VERSION ""

NS_ :

BS_:

BU_: EHR DMS VIC GWS HASy ADAS MRR_L MRR_M MPC CMRR_RL CMRR_RR CMRR_FL CMRR_FR MRR GW AVAP
VAL_TABLE_ ACC_ICON_LADI 2 "Blinking" 1 "Shown" 0 "Not shown" ;
VAL_TABLE_ ShiftInProgress 1 "shift in progress" 0 "no shift" ;
VAL_TABLE_ ACC_Minimale_Bremsung 1 "Anford_Min_Bremsung_aktiv" 0 "Anford_Min_Bremsung_nicht_aktiv" ;
VAL_TABLE_ ADAS_Lvl_HBA 7 "Reserved" 6 "Reserved" 5 "Reserved" 4 "Reserved" 3 "Level 3" 2 "Level 2" 1 "Level 1" 0 "Level 0" ;
VAL_TABLE_ ADAS_Req_Prefill 1 "Active" 0 "Not Active" ;
VAL_TABLE_ ADAS_Req_AWB 1 "Active" 0 "Not Active" ;
VAL_TABLE_ ADAS_Req_HBA 1 "Active" 0 "Not active" ;
VAL_TABLE_ ADAS_Lvl_AWB 7 "Level 7" 6 "Level 6" 5 "Level 5" 4 "Level 4" 3 "Level 3" 2 "Level 2" 1 "Level 1" 0 "No Request" ;
VAL_TABLE_ ADAS_DecelTyp_AEB 15 "Reserved" 14 "Reserved" 13 "Reserved" 12 "Reserved" 11 "Reserved" 10 "Reserved" 9 "Reserved" 8 "Reserved" 7 "Reserved" 6 "Reserved" 5 "FCTB" 4 "EBA" 3 "AEB~CYCLIST" 2 "AEB~VRU" 1 "AEB" 0 "Default" ;
VAL_TABLE_ ADAS_0x4BA_HMI 15 "off" 14 "reserved" 13 "reserved" 12 "reserved" 11 "reserved" 10 "reserved" 9 "reserved" 8 "blueFlashing" 7 "blueBreathing" 6 "greenFlashing" 5 "greenBreathing" 4 "red/purple" 3 "yellow" 2 "green" 1 "blue" 0 "white" ;

BO_ 3221225472 VECTOR__INDEPENDENT_SIG_MSG: 0 Vector__XXX
 SG_ GRA_ACC_01_CRC : 0|8@1+ (1,0) [0|255] "" Vector__XXX

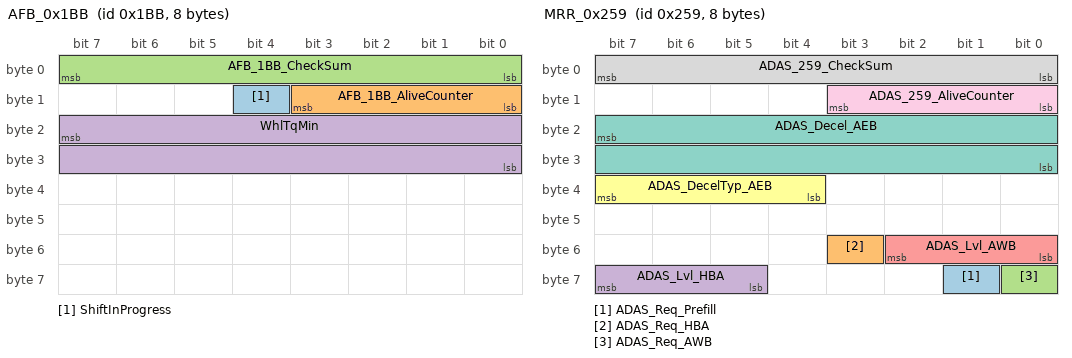
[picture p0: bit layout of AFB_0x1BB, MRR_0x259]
BO_ 443 AFB_0x1BB: 8 HASy
 SG_ ShiftInProgress : 12|1@0+ (1,0) [0|1] ""  ADAS
 SG_ AFB_1BB_AliveCounter : 11|4@0+ (1,0) [0|15] ""  ADAS
 SG_ AFB_1BB_CheckSum : 7|8@0+ (1,0) [0|255] ""  ADAS
 SG_ WhlTqMin : 23|16@0+ (1,-32768) [-32768|32767] "Nm"  ADAS

BO_ 601 MRR_0x259: 8 MRR
 SG_ ADAS_Req_Prefill : 57|1@0+ (1,0) [0|1] ""  GW
 SG_ ADAS_Req_HBA : 51|1@0+ (1,0) [0|1] ""  GW
 SG_ ADAS_Req_AWB : 56|1@0+ (1,0) [0|1] ""  GW
 SG_ ADAS_Lvl_HBA : 63|3@0+ (1,0) [0|7] ""  GW
 SG_ ADAS_Lvl_AWB : 50|3@0+ (1,0) [0|7] ""  GW
 SG_ ADAS_DecelTyp_AEB : 39|4@0+ (1,0) [0|15] ""  GW
 SG_ ADAS_Decel_AEB : 23|16@0+ (0.0004882,-16) [-16|15.994187] "m/s²"  GW
 SG_ ADAS_259_CheckSum : 7|8@0+ (1,0) [0|255] ""  GW
 SG_ ADAS_259_AliveCounter : 11|4@0+ (1,0) [0|15] ""  GW

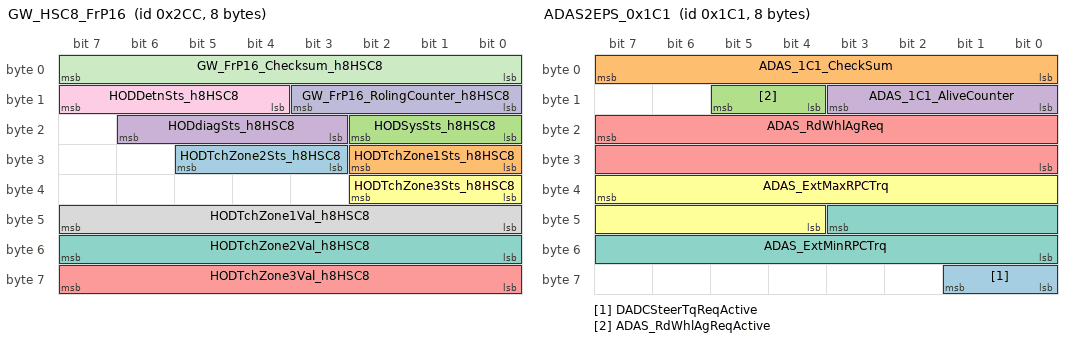
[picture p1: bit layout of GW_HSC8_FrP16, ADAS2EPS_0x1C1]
BO_ 716 GW_HSC8_FrP16: 8 GW
 SG_ HODTchZone2Sts_h8HSC8 : 27|3@1+ (1,0) [0|7] ""  ADAS
 SG_ HODTchZone1Sts_h8HSC8 : 24|3@1+ (1,0) [0|7] ""  ADAS
 SG_ HODSysSts_h8HSC8 : 16|3@1+ (1,0) [0|7] ""  ADAS
 SG_ HODdiagSts_h8HSC8 : 19|4@1+ (1,0) [0|15] ""  ADAS
 SG_ HODTchZone3Val_h8HSC8 : 56|8@1+ (1,0) [0|255] ""  ADAS
 SG_ HODTchZone3Sts_h8HSC8 : 32|3@1+ (1,0) [0|7] ""  ADAS
 SG_ HODTchZone2Val_h8HSC8 : 48|8@1+ (1,0) [0|255] ""  ADAS
 SG_ HODTchZone1Val_h8HSC8 : 40|8@1+ (1,0) [0|255] ""  ADAS
 SG_ HODDetnSts_h8HSC8 : 12|4@1+ (1,0) [0|15] ""  ADAS
 SG_ GW_FrP16_RolingCounter_h8HSC8 : 8|4@1+ (1,0) [0|15] ""  ADAS
 SG_ GW_FrP16_Checksum_h8HSC8 : 0|8@1+ (1,0) [0|255] ""  ADAS

BO_ 449 ADAS2EPS_0x1C1: 8 ADAS
 SG_ DADCSteerTqReqActive : 57|2@0+ (1,0) [0|3] ""  HASy
 SG_ ADAS_1C1_CheckSum : 7|8@0+ (1,0) [0|255] ""  HASy
 SG_ ADAS_RdWhlAgReqActive : 13|2@0+ (1,0) [0|3] ""  HASy
 SG_ ADAS_1C1_AliveCounter : 11|4@0+ (1,0) [0|15] ""  HASy
 SG_ ADAS_RdWhlAgReq : 23|16@0+ (0.005,-45) [-45|45] "degree"  HASy
 SG_ ADAS_ExtMaxRPCTrq : 39|12@0+ (0.02,-20.48) [-20.48|20.46] "Nm"  HASy
 SG_ ADAS_ExtMinRPCTrq : 43|12@0+ (0.02,-20.48) [-20.48|20.46] "Nm"  HASy

BO_ 1216 HDM_GF: 32 EHR
 SG_ GF_map_position_accuracy : 200|12@1+ (1,0) [0|4095] "cm"  ADAS
 SG_ GF_map_position_deviation : 188|12@1+ (1,0) [0|4095] "cm"  ADAS
 SG_ GF_CRC : 0|16@1+ (1,0) [0|65535] ""  ADAS
 SG_ GF_AliveCtr : 16|8@1+ (1,0) [0|255] ""  ADAS
 SG_ GF_Currentlane_Index : 176|8@1+ (1,0) [0|255] ""  ADAS
 SG_ GF_NumberOfLanes : 184|4@1+ (1,0) [0|15] ""  ADAS
 SG_ GF_Region_outOfODD_offset : 24|10@1+ (1,0) [0|1023] "m"  ADAS
 SG_ GF_Country_outOfODD_offset : 34|10@1+ (1,0) [0|1023] "m"  ADAS
 SG_ GF_LaneTrans_outOfODD_offset : 44|10@1+ (1,0) [0|1023] "m"  ADAS
 SG_ GF_Curvature_outOfODD_offset : 54|10@1+ (1,0) [0|1023] "m"  ADAS
 SG_ GF_LaneType_outOfODD_offset : 64|10@1+ (1,0) [0|1023] "m"  ADAS
 SG_ GF_RoadSlope_outOfODD_offset : 74|10@1+ (1,0) [0|1023] "m"  ADAS
 SG_ GF_LaneWidth_outOfODD_offset : 84|10@1+ (1,0) [0|1023] "m"  ADAS
 SG_ GF_FormOfWay_outOfODD_offset : 94|10@1+ (1,0) [0|1023] "m"  ADAS
 SG_ GF_MapExpired : 224|1@1+ (1,0) [0|1] "boolean"  ADAS
 SG_ GF_BlackListedSegment_offset : 114|10@1+ (1,0) [0|1023] "m"  ADAS
 SG_ GF_Intersection_offset : 104|10@1+ (1,0) [0|1023] "m"  ADAS
 SG_ GF_SideWind_offset : 124|10@1+ (1,0) [0|1023] "m"  ADAS
 SG_ GF_ActiveSpeedLimit : 168|8@1+ (1,0) [0|255] "km/h"  ADAS
 SG_ GF_TollGate_offset : 134|10@1+ (1,0) [0|1023] "m"  ADAS
 SG_ GF_TrafficLight_offset : 144|10@1+ (1,0) [0|1023] "m"  ADAS
 SG_ GF_Tunnel_Offset : 154|10@1+ (1,0) [0|1023] "m"  ADAS
 SG_ GF_MapStatus : 212|10@1+ (1,0) [0|1023] ""  ADAS

BO_ 1217 HDM_Curv: 64 EHR
 SG_ Cv_CRC : 0|16@1+ (1,0) [0|65535] ""  ADAS
 SG_ Cv_AliveCtr : 16|8@1+ (1,0) [0|255] ""  ADAS
 SG_ Cv_Value_Seg00 : 32|10@1+ (0.0001,0) [0|0.1] "1/m"  ADAS
 SG_ Cv_Value_Seg01 : 42|10@1+ (0.0001,0) [0|0.1] "1/m"  ADAS
 SG_ Cv_Value_Seg02 : 52|10@1+ (0.0001,0) [0|0.1] "1/m"  ADAS
 SG_ Cv_Value_Seg03 : 62|10@1+ (0.0001,0) [0|0.1] "1/m"  ADAS
 SG_ Cv_Value_Seg04 : 72|10@1+ (0.0001,0) [0|0.1] "1/m"  ADAS
 SG_ Cv_Value_Seg05 : 82|10@1+ (0.0001,0) [0|0.1] "1/m"  ADAS
 SG_ Cv_Value_Seg06 : 92|10@1+ (0.0001,0) [0|0.1] "1/m"  ADAS
 SG_ Cv_Value_Seg07 : 102|10@1+ (0.0001,0) [0|0.1] "1/m"  ADAS
 SG_ Cv_Value_Seg08 : 112|10@1+ (0.0001,0) [0|0.1] "1/m"  ADAS
 SG_ Cv_Value_Seg09 : 122|10@1+ (0.0001,0) [0|0.1] "1/m"  ADAS
 SG_ Cv_Value_Seg10 : 132|10@1+ (0.0001,0) [0|0.1] "1/m"  ADAS
 SG_ Cv_Value_Seg11 : 142|10@1+ (0.0001,0) [0|0.1] "1/m"  ADAS
 SG_ Cv_Value_Seg12 : 152|10@1+ (0.0001,0) [0|0.1] "1/m"  ADAS
 SG_ Cv_Value_Seg13 : 162|10@1+ (0.0001,0) [0|0.1] "1/m"  ADAS
 SG_ Cv_Value_Seg14 : 172|10@1+ (0.0001,0) [0|0.1] "1/m"  ADAS
 SG_ Cv_Value_Seg15 : 182|10@1+ (0.0001,0) [0|0.1] "1/m"  ADAS
 SG_ Cv_Value_Seg16 : 192|10@1+ (0.0001,0) [0|0.1] "1/m"  ADAS
 SG_ Cv_Value_Seg17 : 202|10@1+ (0.0001,0) [0|0.1] "1/m"  ADAS
 SG_ Cv_Value_Seg18 : 212|10@1+ (0.0001,0) [0|0.1] "1/m"  ADAS
 SG_ Cv_Value_Seg19 : 222|10@1+ (0.0001,0) [0|0.1] "1/m"  ADAS
 SG_ Cv_Offset_Seg00 : 232|10@1+ (1,0) [0|1023] "m"  ADAS
 SG_ Cv_Offset_Seg01 : 242|10@1+ (1,0) [0|1023] "m"  ADAS
 SG_ Cv_Offset_Seg02 : 252|10@1+ (1,0) [0|1023] "m"  ADAS
 SG_ Cv_Offset_Seg03 : 262|10@1+ (1,0) [0|1023] "m"  ADAS
 SG_ Cv_Offset_Seg04 : 272|10@1+ (1,0) [0|1023] "m"  ADAS
 SG_ Cv_Offset_Seg05 : 282|10@1+ (1,0) [0|1023] "m"  ADAS
 SG_ Cv_Offset_Seg06 : 292|10@1+ (1,0) [0|1023] "m"  ADAS
 SG_ Cv_Offset_Seg07 : 302|10@1+ (1,0) [0|1023] "m"  ADAS
 SG_ Cv_Offset_Seg08 : 312|10@1+ (1,0) [0|1023] "m"  ADAS
 SG_ Cv_Offset_Seg09 : 322|10@1+ (1,0) [0|1023] "m"  ADAS
 SG_ Cv_Offset_Seg10 : 332|10@1+ (1,0) [0|1023] "m"  ADAS
 SG_ Cv_Offset_Seg11 : 342|10@1+ (1,0) [0|1023] "m"  ADAS
 SG_ Cv_Offset_Seg12 : 352|10@1+ (1,0) [0|1023] "m"  ADAS
 SG_ Cv_Offset_Seg13 : 362|10@1+ (1,0) [0|1023] "m"  ADAS
 SG_ Cv_Offset_Seg14 : 372|10@1+ (1,0) [0|1023] "m"  ADAS
 SG_ Cv_Offset_Seg15 : 382|10@1+ (1,0) [0|1023] "m"  ADAS
 SG_ Cv_Offset_Seg16 : 392|10@1+ (1,0) [0|1023] "m"  ADAS
 SG_ Cv_Offset_Seg17 : 402|10@1+ (1,0) [0|1023] "m"  ADAS
 SG_ Cv_Offset_Seg18 : 412|10@1+ (1,0) [0|1023] "m"  ADAS
 SG_ Cv_Offset_Seg19 : 422|10@1+ (1,0) [0|1023] "m"  ADAS

BO_ 1220 HDM_Central_Line_M: 24 EHR
 SG_ centerline_m_CRC : 0|16@1+ (1,0) [0|65535] ""  ADAS
 SG_ centerline_m_AliveCtr : 16|8@1+ (1,0) [0|255] ""  ADAS
 SG_ centerline_m_BlockCtr : 24|4@1+ (1,0) [0|15] ""  ADAS
 SG_ CenterPoint_dx_m01 : 28|10@1+ (0.05,-50) [-50|0] "m"  ADAS
 SG_ CenterPoint_dy_m01 : 38|12@1+ (0.05,-102.4) [-102.4|102.35] "m"  ADAS
 SG_ CenterPoint_dx_m02 : 50|10@1+ (0.05,-50) [-50|0] "m"  ADAS
 SG_ CenterPoint_dy_m02 : 60|12@1+ (0.05,-102.4) [-102.4|102.35] "m"  ADAS
 SG_ CenterPoint_dx_m03 : 72|10@1+ (0.05,-50) [-50|0] "m"  ADAS
 SG_ CenterPoint_dy_m03 : 82|12@1+ (0.05,-102.4) [-102.4|102.35] "m"  ADAS
 SG_ CenterPoint_dx_m04 : 94|10@1+ (0.05,-50) [-50|0] "m"  ADAS
 SG_ CenterPoint_dy_m04 : 104|12@1+ (0.05,-102.4) [-102.4|102.35] "m"  ADAS
 SG_ MAP_TimeSync : 116|48@1+ (1,0) [0|39636172800000] "ms"  ADAS

BO_ 1218 HDM_Centerline_1: 64 EHR
 SG_ centerline_1_CRC : 0|16@1+ (1,0) [0|65535] ""  ADAS
 SG_ centerline_1_AliveCtr : 16|8@1+ (1,0) [0|255] ""  ADAS
 SG_ CenterPoint_dx_00 : 24|12@1+ (0.05,0) [0|204.75] "m"  ADAS
 SG_ CenterPoint_dy_00 : 36|12@1+ (0.05,-102.4) [-102.4|102.35] "m"  ADAS
 SG_ CenterPoint_dx_01 : 48|12@1+ (0.05,0) [0|204.75] "m"  ADAS
 SG_ CenterPoint_dy_01 : 60|12@1+ (0.05,-102.4) [-102.4|102.35] "m"  ADAS
 SG_ CenterPoint_dx_02 : 72|12@1+ (0.05,0) [0|204.75] "m"  ADAS
 SG_ CenterPoint_dy_02 : 84|12@1+ (0.05,-102.4) [-102.4|102.35] "m"  ADAS
 SG_ CenterPoint_dx_03 : 96|12@1+ (0.05,0) [0|204.75] "m"  ADAS
 SG_ CenterPoint_dy_03 : 108|12@1+ (0.05,-102.4) [-102.4|102.35] "m"  ADAS
 SG_ CenterPoint_dx_04 : 120|12@1+ (0.05,0) [0|204.75] "m"  ADAS
 SG_ CenterPoint_dy_04 : 132|12@1+ (0.05,-102.4) [-102.4|102.35] "m"  ADAS
 SG_ CenterPoint_dx_05 : 144|12@1+ (0.05,0) [0|204.75] "m"  ADAS
 SG_ CenterPoint_dy_05 : 156|12@1+ (0.05,-102.4) [-102.4|102.35] "m"  ADAS
 SG_ CenterPoint_dx_06 : 168|12@1+ (0.05,0) [0|204.75] "m"  ADAS
 SG_ CenterPoint_dy_06 : 180|12@1+ (0.05,-102.4) [-102.4|102.35] "m"  ADAS
 SG_ CenterPoint_dx_07 : 192|12@1+ (0.05,0) [0|204.75] "m"  ADAS
 SG_ CenterPoint_dy_07 : 204|12@1+ (0.05,-102.4) [-102.4|102.35] "m"  ADAS
 SG_ CenterPoint_dx_08 : 216|12@1+ (0.05,0) [0|204.75] "m"  ADAS
 SG_ CenterPoint_dy_08 : 228|12@1+ (0.05,-102.4) [-102.4|102.35] "m"  ADAS
 SG_ CenterPoint_dx_09 : 240|12@1+ (0.05,0) [0|204.75] "m"  ADAS
 SG_ CenterPoint_dy_09 : 252|12@1+ (0.05,-102.4) [-102.4|102.35] "m"  ADAS
 SG_ CenterPoint_dx_10 : 264|12@1+ (0.05,0) [0|204.75] "m"  ADAS
 SG_ CenterPoint_dy_10 : 276|12@1+ (0.05,-102.4) [-102.4|102.35] "m"  ADAS
 SG_ CenterPoint_dx_11 : 288|12@1+ (0.05,0) [0|204.75] "m"  ADAS
 SG_ CenterPoint_dy_11 : 300|12@1+ (0.05,-102.4) [-102.4|102.35] "m"  ADAS
 SG_ CenterPoint_dx_12 : 312|12@1+ (0.05,0) [0|204.75] "m"  ADAS
 SG_ CenterPoint_dy_12 : 324|12@1+ (0.05,-102.4) [-102.4|102.35] "m"  ADAS
 SG_ CenterPoint_dx_13 : 336|12@1+ (0.05,0) [0|204.75] "m"  ADAS
 SG_ CenterPoint_dy_13 : 348|12@1+ (0.05,-102.4) [-102.4|102.35] "m"  ADAS
 SG_ CenterPoint_dx_14 : 360|12@1+ (0.05,0) [0|204.75] "m"  ADAS
 SG_ CenterPoint_dy_14 : 372|12@1+ (0.05,-102.4) [-102.4|102.35] "m"  ADAS
 SG_ CenterPoint_dx_15 : 384|12@1+ (0.05,0) [0|204.75] "m"  ADAS
 SG_ CenterPoint_dy_15 : 396|12@1+ (0.05,-102.4) [-102.4|102.35] "m"  ADAS
 SG_ CenterPoint_dx_16 : 408|12@1+ (0.05,0) [0|204.75] "m"  ADAS
 SG_ CenterPoint_dy_16 : 420|12@1+ (0.05,-102.4) [-102.4|102.35] "m"  ADAS
 SG_ CenterPoint_dx_17 : 432|12@1+ (0.05,0) [0|204.75] "m"  ADAS
 SG_ CenterPoint_dy_17 : 444|12@1+ (0.05,-102.4) [-102.4|102.35] "m"  ADAS
 SG_ CenterPoint_dx_18 : 456|12@1+ (0.05,0) [0|204.75] "m"  ADAS
 SG_ CenterPoint_dy_18 : 468|12@1+ (0.05,-102.4) [-102.4|102.35] "m"  ADAS
 SG_ CenterPoint_dx_19 : 480|12@1+ (0.05,0) [0|204.75] "m"  ADAS
 SG_ CenterPoint_dy_19 : 492|12@1+ (0.05,-102.4) [-102.4|102.35] "m"  ADAS
 SG_ centerline_1_BlockCtr : 504|4@1+ (1,0) [0|15] ""  ADAS

BO_ 1219 HDM_Centerline_2: 64 EHR
 SG_ centerline_2_CRC : 0|16@1+ (1,0) [0|65535] ""  ADAS
 SG_ centerline_2_AliveCtr : 16|8@1+ (1,0) [0|255] ""  ADAS
 SG_ CenterPoint_dx_20 : 24|12@1+ (0.05,0) [0|204.75] "m"  ADAS
 SG_ CenterPoint_dy_20 : 36|12@1+ (0.05,-102.4) [-102.4|102.35] "m"  ADAS
 SG_ CenterPoint_dx_21 : 48|12@1+ (0.05,0) [0|204.75] "m"  ADAS
 SG_ CenterPoint_dy_21 : 60|12@1+ (0.05,-102.4) [-102.4|102.35] "m"  ADAS
 SG_ CenterPoint_dx_22 : 72|12@1+ (0.05,0) [0|204.75] "m"  ADAS
 SG_ CenterPoint_dy_22 : 84|12@1+ (0.05,-102.4) [-102.4|102.35] "m"  ADAS
 SG_ CenterPoint_dx_23 : 96|12@1+ (0.05,0) [0|204.75] "m"  ADAS
 SG_ CenterPoint_dy_23 : 108|12@1+ (0.05,-102.4) [-102.4|102.35] "m"  ADAS
 SG_ CenterPoint_dx_24 : 120|12@1+ (0.05,0) [0|204.75] "m"  ADAS
 SG_ CenterPoint_dy_24 : 132|12@1+ (0.05,-102.4) [-102.4|102.35] "m"  ADAS
 SG_ CenterPoint_dx_25 : 144|12@1+ (0.05,0) [0|204.75] "m"  ADAS
 SG_ CenterPoint_dy_25 : 156|12@1+ (0.05,-102.4) [-102.4|102.35] "m"  ADAS
 SG_ CenterPoint_dx_26 : 168|12@1+ (0.05,0) [0|204.75] "m"  ADAS
 SG_ CenterPoint_dy_26 : 180|12@1+ (0.05,-102.4) [-102.4|102.35] "m"  ADAS
 SG_ CenterPoint_dx_27 : 192|12@1+ (0.05,0) [0|204.75] "m"  ADAS
 SG_ CenterPoint_dy_27 : 204|12@1+ (0.05,-102.4) [-102.4|102.35] "m"  ADAS
 SG_ CenterPoint_dx_28 : 216|12@1+ (0.05,0) [0|204.75] "m"  ADAS
 SG_ CenterPoint_dy_28 : 228|12@1+ (0.05,-102.4) [-102.4|102.35] "m"  ADAS
 SG_ CenterPoint_dx_29 : 240|12@1+ (0.05,0) [0|204.75] "m"  ADAS
 SG_ CenterPoint_dy_29 : 252|12@1+ (0.05,-102.4) [-102.4|102.35] "m"  ADAS
 SG_ CenterPoint_dx_30 : 264|12@1+ (0.05,0) [0|204.75] "m"  ADAS
 SG_ CenterPoint_dy_30 : 276|12@1+ (0.05,-102.4) [-102.4|102.35] "m"  ADAS
 SG_ CenterPoint_dx_31 : 288|12@1+ (0.05,0) [0|204.75] "m"  ADAS
 SG_ CenterPoint_dy_31 : 300|12@1+ (0.05,-102.4) [-102.4|102.35] "m"  ADAS
 SG_ CenterPoint_dx_32 : 312|12@1+ (0.05,0) [0|204.75] "m"  ADAS
 SG_ CenterPoint_dy_32 : 324|12@1+ (0.05,-102.4) [-102.4|102.35] "m"  ADAS
 SG_ CenterPoint_dx_33 : 336|12@1+ (0.05,0) [0|204.75] "m"  ADAS
 SG_ CenterPoint_dy_33 : 348|12@1+ (0.05,-102.4) [-102.4|102.35] "m"  ADAS
 SG_ CenterPoint_dx_34 : 360|12@1+ (0.05,0) [0|204.75] "m"  ADAS
 SG_ CenterPoint_dy_34 : 372|12@1+ (0.05,-102.4) [-102.4|102.35] "m"  ADAS
 SG_ centerline_LaneWidth : 384|9@1+ (1,0) [0|511] "cm"  ADAS
 SG_ localization_lat_StdDev : 393|12@1+ (0.01,0) [0|40.95] "m"  ADAS
 SG_ localization_long_StdDev : 405|12@1+ (0.01,0) [0|40.95] "m"  ADAS
 SG_ localization_heading_StdDev : 417|11@1+ (0.1,0) [0|204.7] "degree"  ADAS
 SG_ map_position_deviation : 428|12@1+ (1,0) [0|4095] "cm"  ADAS
 SG_ map_position_accuracy : 440|12@1+ (1,0) [0|4095] "cm"  ADAS
 SG_ Timestamp : 452|20@1+ (0.00065536,0) [0|687.194112] "s"  ADAS
 SG_ centerline_2_BlockCtr : 472|4@1+ (1,0) [0|15] ""  ADAS

BO_ 1221 HDM_Central_Line_HighR: 64 EHR
 SG_ centerline_HR_CRC : 0|16@1+ (1,0) [0|65535] ""  ADAS
 SG_ centerline_HR_AliveCtr : 16|8@1+ (1,0) [0|255] ""  ADAS
 SG_ centerline_HR_BlockCtr : 24|4@1+ (1,0) [0|15] ""  ADAS
 SG_ CenterPoint_dx_m01_HighR : 28|6@1+ (0.001,0) [0|0.049] "m"  ADAS
 SG_ CenterPoint_dy_m01_HighR : 34|6@1+ (0.001,0) [0|0.049] "m"  ADAS
 SG_ CenterPoint_dy_m02_HighR : 40|6@1+ (0.001,0) [0|0.049] "m"  ADAS
 SG_ CenterPoint_dx_m02_HighR : 46|6@1+ (0.001,0) [0|0.049] "m"  ADAS
 SG_ CenterPoint_dy_m03_HighR : 52|6@1+ (0.001,0) [0|0.049] "m"  ADAS
 SG_ CenterPoint_dx_m03_HighR : 58|6@1+ (0.001,0) [0|0.049] "m"  ADAS
 SG_ CenterPoint_dy_m04_HighR : 64|6@1+ (0.001,0) [0|0.049] "m"  ADAS
 SG_ CenterPoint_dx_m04_HighR : 70|6@1+ (0.001,0) [0|0.049] "m"  ADAS
 SG_ CenterPoint_dy_00_HighR : 76|6@1+ (0.001,0) [0|0.049] "m"  ADAS
 SG_ CenterPoint_dx_00_HighR : 82|6@1+ (0.001,0) [0|0.049] "m"  ADAS
 SG_ CenterPoint_dy_01_HighR : 88|6@1+ (0.001,0) [0|0.049] "m"  ADAS
 SG_ CenterPoint_dx_01_HighR : 94|6@1+ (0.001,0) [0|0.049] "m"  ADAS
 SG_ CenterPoint_dy_02_HighR : 100|6@1+ (0.001,0) [0|0.049] "m"  ADAS
 SG_ CenterPoint_dx_02_HighR : 106|6@1+ (0.001,0) [0|0.049] "m"  ADAS
 SG_ CenterPoint_dy_03_HighR : 112|6@1+ (0.001,0) [0|0.049] "m"  ADAS
 SG_ CenterPoint_dx_03_HighR : 118|6@1+ (0.001,0) [0|0.049] "m"  ADAS
 SG_ CenterPoint_dy_04_HighR : 124|6@1+ (0.001,0) [0|0.049] "m"  ADAS
 SG_ CenterPoint_dx_04_HighR : 130|6@1+ (0.001,0) [0|0.049] "m"  ADAS
 SG_ CenterPoint_dy_05_HighR : 136|6@1+ (0.001,0) [0|0.049] "m"  ADAS
 SG_ CenterPoint_dx_05_HighR : 142|6@1+ (0.001,0) [0|0.049] "m"  ADAS
 SG_ CenterPoint_dy_06_HighR : 148|6@1+ (0.001,0) [0|0.049] "m"  ADAS
 SG_ CenterPoint_dx_06_HighR : 154|6@1+ (0.001,0) [0|0.049] "m"  ADAS
 SG_ CenterPoint_dy_07_HighR : 160|6@1+ (0.001,0) [0|0.049] "m"  ADAS
 SG_ CenterPoint_dx_07_HighR : 166|6@1+ (0.001,0) [0|0.049] "m"  ADAS
 SG_ CenterPoint_dy_08_HighR : 172|6@1+ (0.001,0) [0|0.049] "m"  ADAS
 SG_ CenterPoint_dx_08_HighR : 178|6@1+ (0.001,0) [0|0.049] "m"  ADAS
 SG_ CenterPoint_dy_09_HighR : 184|6@1+ (0.001,0) [0|0.049] "m"  ADAS
 SG_ CenterPoint_dx_09_HighR : 190|6@1+ (0.001,0) [0|0.049] "m"  ADAS
 SG_ CenterPoint_dy_10_HighR : 196|6@1+ (0.001,0) [0|0.049] "m"  ADAS
 SG_ CenterPoint_dx_10_HighR : 202|6@1+ (0.001,0) [0|0.049] "m"  ADAS
 SG_ CenterPoint_dy_11_HighR : 208|6@1+ (0.001,0) [0|0.049] "m"  ADAS
 SG_ CenterPoint_dx_11_HighR : 214|6@1+ (0.001,0) [0|0.049] "m"  ADAS
 SG_ CenterPoint_dy_12_HighR : 220|6@1+ (0.001,0) [0|0.049] "m"  ADAS
 SG_ CenterPoint_dx_12_HighR : 226|6@1+ (0.001,0) [0|0.049] "m"  ADAS
 SG_ CenterPoint_dy_13_HighR : 232|6@1+ (0.001,0) [0|0.049] "m"  ADAS
 SG_ CenterPoint_dx_13_HighR : 238|6@1+ (0.001,0) [0|0.049] "m"  ADAS
 SG_ CenterPoint_dy_14_HighR : 244|6@1+ (0.001,0) [0|0.049] "m"  ADAS
 SG_ CenterPoint_dx_14_HighR : 250|6@1+ (0.001,0) [0|0.049] "m"  ADAS
 SG_ CenterPoint_dy_15_HighR : 256|6@1+ (0.001,0) [0|0.049] "m"  ADAS
 SG_ CenterPoint_dx_15_HighR : 262|6@1+ (0.001,0) [0|0.049] "m"  ADAS
 SG_ CenterPoint_dy_16_HighR : 268|6@1+ (0.001,0) [0|0.049] "m"  ADAS
 SG_ CenterPoint_dx_16_HighR : 274|6@1+ (0.001,0) [0|0.049] "m"  ADAS
 SG_ CenterPoint_dy_17_HighR : 280|6@1+ (0.001,0) [0|0.049] "m"  ADAS
 SG_ CenterPoint_dx_17_HighR : 286|6@1+ (0.001,0) [0|0.049] "m"  ADAS
 SG_ CenterPoint_dy_18_HighR : 292|6@1+ (0.001,0) [0|0.049] "m"  ADAS
 SG_ CenterPoint_dx_18_HighR : 298|6@1+ (0.001,0) [0|0.049] "m"  ADAS
 SG_ CenterPoint_dy_19_HighR : 304|6@1+ (0.001,0) [0|0.049] "m"  ADAS
 SG_ CenterPoint_dx_19_HighR : 310|6@1+ (0.001,0) [0|0.049] "m"  ADAS
 SG_ CenterPoint_dy_20_HighR : 316|6@1+ (0.001,0) [0|0.049] "m"  ADAS
 SG_ CenterPoint_dx_20_HighR : 322|6@1+ (0.001,0) [0|0.049] "m"  ADAS
 SG_ CenterPoint_dy_21_HighR : 328|6@1+ (0.001,0) [0|0.049] "m"  ADAS
 SG_ CenterPoint_dx_21_HighR : 334|6@1+ (0.001,0) [0|0.049] "m"  ADAS
 SG_ CenterPoint_dy_22_HighR : 340|6@1+ (0.001,0) [0|0.049] "m"  ADAS
 SG_ CenterPoint_dx_22_HighR : 346|6@1+ (0.001,0) [0|0.049] "m"  ADAS
 SG_ CenterPoint_dy_23_HighR : 352|6@1+ (0.001,0) [0|0.049] "m"  ADAS
 SG_ CenterPoint_dx_23_HighR : 358|6@1+ (0.001,0) [0|0.049] "m"  ADAS
 SG_ CenterPoint_dy_24_HighR : 364|6@1+ (0.001,0) [0|0.049] "m"  ADAS
 SG_ CenterPoint_dx_24_HighR : 370|6@1+ (0.001,0) [0|0.049] "m"  ADAS
 SG_ CenterPoint_dy_25_HighR : 376|6@1+ (0.001,0) [0|0.049] "m"  ADAS
 SG_ CenterPoint_dx_25_HighR : 382|6@1+ (0.001,0) [0|0.049] "m"  ADAS
 SG_ CenterPoint_dy_26_HighR : 388|6@1+ (0.001,0) [0|0.049] "m"  ADAS
 SG_ CenterPoint_dx_26_HighR : 394|6@1+ (0.001,0) [0|0.049] "m"  ADAS
 SG_ CenterPoint_dy_27_HighR : 400|6@1+ (0.001,0) [0|0.049] "m"  ADAS
 SG_ CenterPoint_dx_27_HighR : 406|6@1+ (0.001,0) [0|0.049] "m"  ADAS
 SG_ CenterPoint_dy_28_HighR : 412|6@1+ (0.001,0) [0|0.049] "m"  ADAS
 SG_ CenterPoint_dx_28_HighR : 418|6@1+ (0.001,0) [0|0.049] "m"  ADAS
 SG_ CenterPoint_dy_29_HighR : 424|6@1+ (0.001,0) [0|0.049] "m"  ADAS
 SG_ CenterPoint_dx_29_HighR : 430|6@1+ (0.001,0) [0|0.049] "m"  ADAS
 SG_ CenterPoint_dy_30_HighR : 436|6@1+ (0.001,0) [0|0.049] "m"  ADAS
 SG_ CenterPoint_dx_30_HighR : 442|6@1+ (0.001,0) [0|0.049] "m"  ADAS
 SG_ CenterPoint_dy_31_HighR : 448|6@1+ (0.001,0) [0|0.049] "m"  ADAS
 SG_ CenterPoint_dx_31_HighR : 454|6@1+ (0.001,0) [0|0.049] "m"  ADAS
 SG_ CenterPoint_dy_32_HighR : 460|6@1+ (0.001,0) [0|0.049] "m"  ADAS
 SG_ CenterPoint_dx_32_HighR : 466|6@1+ (0.001,0) [0|0.049] "m"  ADAS
 SG_ CenterPoint_dy_33_HighR : 472|6@1+ (0.001,0) [0|0.049] "m"  ADAS
 SG_ CenterPoint_dx_33_HighR : 478|6@1+ (0.001,0) [0|0.049] "m"  ADAS
 SG_ CenterPoint_dy_34_HighR : 484|6@1+ (0.001,0) [0|0.049] "m"  ADAS
 SG_ CenterPoint_dx_34_HighR : 490|6@1+ (0.001,0) [0|0.049] "m"  ADAS

BO_ 1226 EHR_ReferenceLine1_0x4CA: 64 EHR
 SG_ ReferenceLine1_CRC : 0|16@1+ (1,0) [0|65535] ""  ADAS
 SG_ ReferenceLine1_AliveCtr : 16|8@1+ (1,0) [0|255] ""  ADAS
 SG_ ReferenceLine1_TimeStamp : 24|20@1+ (0.00065536,0) [0|687.194] "s"  ADAS
 SG_ ReferenceLine_point_N : 44|6@1+ (1,0) [0|63] ""  ADAS
 SG_ ReferenceLine_dx_00 : 50|12@1+ (0.05,0) [0|204.75] "m"  ADAS
 SG_ ReferenceLine_dy_00 : 62|12@1+ (0.05,-102.4) [-102.4|102.35] "m"  ADAS
 SG_ ReferenceLine_dx_01 : 74|12@1+ (0.05,0) [0|204.75] "m"  ADAS
 SG_ ReferenceLine_dy_01 : 86|12@1+ (0.05,-102.4) [-102.4|102.35] "m"  ADAS
 SG_ ReferenceLine_dx_02 : 98|12@1+ (0.05,0) [0|204.75] "m"  ADAS
 SG_ ReferenceLine_dy_02 : 110|12@1+ (0.05,-102.4) [-102.4|102.35] "m"  ADAS
 SG_ ReferenceLine_dx_03 : 122|12@1+ (0.05,0) [0|204.75] "m"  ADAS
 SG_ ReferenceLine_dy_03 : 134|12@1+ (0.05,-102.4) [-102.4|102.35] "m"  ADAS
 SG_ ReferenceLine_dx_04 : 146|12@1+ (0.05,0) [0|204.75] "m"  ADAS
 SG_ ReferenceLine_dy_04 : 158|12@1+ (0.05,-102.4) [-102.4|102.35] "m"  ADAS
 SG_ ReferenceLine_dx_05 : 170|12@1+ (0.05,0) [0|204.75] "m"  ADAS
 SG_ ReferenceLine_dy_05 : 182|12@1+ (0.05,-102.4) [-102.4|102.35] "m"  ADAS
 SG_ ReferenceLine_dx_06 : 194|12@1+ (0.05,0) [0|204.75] "m"  ADAS
 SG_ ReferenceLine_dy_06 : 206|12@1+ (0.05,-102.4) [-102.4|102.35] "m"  ADAS
 SG_ ReferenceLine_dx_07 : 218|12@1+ (0.05,0) [0|204.75] "m"  ADAS
 SG_ ReferenceLine_dy_07 : 230|12@1+ (0.05,-102.4) [-102.4|102.35] "m"  ADAS
 SG_ ReferenceLine_dx_08 : 242|12@1+ (0.05,0) [0|204.75] "m"  ADAS
 SG_ ReferenceLine_dy_08 : 254|12@1+ (0.05,-102.4) [-102.4|102.35] "m"  ADAS
 SG_ ReferenceLine_dx_09 : 266|12@1+ (0.05,0) [0|204.75] "m"  ADAS
 SG_ ReferenceLine_dy_09 : 278|12@1+ (0.05,-102.4) [-102.4|102.35] "m"  ADAS
 SG_ ReferenceLine_dx_10 : 290|12@1+ (0.05,0) [0|204.75] "m"  ADAS
 SG_ ReferenceLine_dy_10 : 302|12@1+ (0.05,-102.4) [-102.4|102.35] "m"  ADAS
 SG_ ReferenceLine_dx_11 : 314|12@1+ (0.05,0) [0|204.75] "m"  ADAS
 SG_ ReferenceLine_dy_11 : 326|12@1+ (0.05,-102.4) [-102.4|102.35] "m"  ADAS
 SG_ ReferenceLine_dx_12 : 338|12@1+ (0.05,0) [0|204.75] "m"  ADAS
 SG_ ReferenceLine_dy_12 : 350|12@1+ (0.05,-102.4) [-102.4|102.35] "m"  ADAS
 SG_ ReferenceLine_dx_13 : 362|12@1+ (0.05,0) [0|204.75] "m"  ADAS
 SG_ ReferenceLine_dy_13 : 374|12@1+ (0.05,-102.4) [-102.4|102.35] "m"  ADAS
 SG_ ReferenceLine_dx_14 : 386|12@1+ (0.05,0) [0|204.75] "m"  ADAS
 SG_ ReferenceLine_dy_14 : 398|12@1+ (0.05,-102.4) [-102.4|102.35] "m"  ADAS
 SG_ ReferenceLine_dx_15 : 410|12@1+ (0.05,0) [0|204.75] "m"  ADAS
 SG_ ReferenceLine_dy_15 : 422|12@1+ (0.05,-102.4) [-102.4|102.35] "m"  ADAS
 SG_ ReferenceLine_dx_16 : 434|12@1+ (0.05,0) [0|204.75] "m"  ADAS
 SG_ ReferenceLine_dy_16 : 446|12@1+ (0.05,-102.4) [-102.4|102.35] "m"  ADAS
 SG_ ReferenceLine_dx_17 : 458|12@1+ (0.05,0) [0|204.75] "m"  ADAS
 SG_ ReferenceLine_dy_17 : 470|12@1+ (0.05,-102.4) [-102.4|102.35] "m"  ADAS
 SG_ ReferenceLine_dx_18 : 482|12@1+ (0.05,0) [0|204.75] "m"  ADAS
 SG_ ReferenceLine_dy_18 : 494|12@1+ (0.05,-102.4) [-102.4|102.35] "m"  ADAS

BO_ 1227 EHR_ReferenceLine2_0x4CB: 64 EHR
 SG_ ReferenceLine2_CRC : 0|16@1+ (1,0) [0|65535] ""  ADAS
 SG_ ReferenceLine2_AliveCtr : 16|8@1+ (1,0) [0|255] ""  ADAS
 SG_ ReferenceLine2_TimeStamp : 24|20@1+ (0.00065536,0) [0|687.194] "s"  ADAS
 SG_ ReferenceLine_dx_19 : 44|12@1+ (0.05,0) [0|204.75] "m"  ADAS
 SG_ ReferenceLine_dy_19 : 56|12@1+ (0.05,-102.4) [-102.4|102.35] "m"  ADAS
 SG_ ReferenceLine_dx_20 : 68|12@1+ (0.05,0) [0|204.75] "m"  ADAS
 SG_ ReferenceLine_dy_20 : 80|12@1+ (0.05,-102.4) [-102.4|102.35] "m"  ADAS
 SG_ ReferenceLine_dx_21 : 92|12@1+ (0.05,0) [0|204.75] "m"  ADAS
 SG_ ReferenceLine_dy_21 : 104|12@1+ (0.05,-102.4) [-102.4|102.35] "m"  ADAS
 SG_ ReferenceLine_dx_22 : 116|12@1+ (0.05,0) [0|204.75] "m"  ADAS
 SG_ ReferenceLine_dy_22 : 128|12@1+ (0.05,-102.4) [-102.4|102.35] "m"  ADAS
 SG_ ReferenceLine_dx_23 : 140|12@1+ (0.05,0) [0|204.75] "m"  ADAS
 SG_ ReferenceLine_dy_23 : 152|12@1+ (0.05,-102.4) [-102.4|102.35] "m"  ADAS
 SG_ ReferenceLine_dx_24 : 164|12@1+ (0.05,0) [0|204.75] "m"  ADAS
 SG_ ReferenceLine_dy_24 : 176|12@1+ (0.05,-102.4) [-102.4|102.35] "m"  ADAS
 SG_ ReferenceLine_dx_25 : 188|12@1+ (0.05,0) [0|204.75] "m"  ADAS
 SG_ ReferenceLine_dy_25 : 200|12@1+ (0.05,-102.4) [-102.4|102.35] "m"  ADAS
 SG_ ReferenceLine_dx_26 : 212|12@1+ (0.05,0) [0|204.75] "m"  ADAS
 SG_ ReferenceLine_dy_26 : 224|12@1+ (0.05,-102.4) [-102.4|102.35] "m"  ADAS
 SG_ ReferenceLine_dx_27 : 236|12@1+ (0.05,0) [0|204.75] "m"  ADAS
 SG_ ReferenceLine_dy_27 : 248|12@1+ (0.05,-102.4) [-102.4|102.35] "m"  ADAS
 SG_ ReferenceLine_dx_28 : 260|12@1+ (0.05,0) [0|204.75] "m"  ADAS
 SG_ ReferenceLine_dy_28 : 272|12@1+ (0.05,-102.4) [-102.4|102.35] "m"  ADAS
 SG_ ReferenceLine_dx_29 : 284|12@1+ (0.05,0) [0|204.75] "m"  ADAS
 SG_ ReferenceLine_dy_29 : 296|12@1+ (0.05,-102.4) [-102.4|102.35] "m"  ADAS
 SG_ ReferenceLine_dx_30 : 308|12@1+ (0.05,0) [0|204.75] "m"  ADAS
 SG_ ReferenceLine_dy_30 : 320|12@1+ (0.05,-102.4) [-102.4|102.35] "m"  ADAS
 SG_ ReferenceLine_dx_31 : 332|12@1+ (0.05,0) [0|204.75] "m"  ADAS
 SG_ ReferenceLine_dy_31 : 344|12@1+ (0.05,-102.4) [-102.4|102.35] "m"  ADAS
 SG_ ReferenceLine_dx_32 : 356|12@1+ (0.05,0) [0|204.75] "m"  ADAS
 SG_ ReferenceLine_dy_32 : 368|12@1+ (0.05,-102.4) [-102.4|102.35] "m"  ADAS
 SG_ ReferenceLine_dx_33 : 380|12@1+ (0.05,0) [0|204.75] "m"  ADAS
 SG_ ReferenceLine_dy_33 : 392|12@1+ (0.05,-102.4) [-102.4|102.35] "m"  ADAS
 SG_ ReferenceLine_dx_34 : 404|12@1+ (0.05,0) [0|204.75] "m"  ADAS
 SG_ ReferenceLine_dy_34 : 416|12@1+ (0.05,-102.4) [-102.4|102.35] "m"  ADAS

BO_ 1228 EHR_Ego_Lane_Info1_0x4CC: 48 EHR
 SG_ Ego_Lane_Info1_CRC : 0|16@1+ (1,0) [0|65535] ""  ADAS
 SG_ Ego_Lane_Info1_AliveCtr : 16|8@1+ (1,0) [0|255] ""  ADAS
 SG_ Ego_Lane_Info1_TimeStamp : 24|20@1+ (0.00065536,0) [0|687.194112] "s"  ADAS
 SG_ Ego_Lane_Map_Status : 44|2@1+ (1,0) [0|1] ""  ADAS
 SG_ Ego_Lane_CurrentSpeedLimit : 46|5@1+ (5,0) [0|130] "km/h"  ADAS
 SG_ Ego_Lane_CurrentSpeedLimit_Type : 51|2@1+ (1,0) [0|3] ""  ADAS
 SG_ Ego_Lane_NextSpeedLimit_Value_1 : 53|5@1+ (5,0) [0|130] "km/h"  ADAS
 SG_ Ego_Lane_NextSpeedLimit_Loc_1 : 58|12@1+ (1,0) [0|4000] "m"  ADAS
 SG_ Ego_Lane_NextSpeedLimit_Type_1 : 70|2@1+ (1,0) [0|3] ""  ADAS
 SG_ Ego_Lane_NextSpeedLimit_Value_2 : 72|5@1+ (5,0) [0|130] "km/h"  ADAS
 SG_ Ego_Lane_NextSpeedLimit_Loc_2 : 77|12@1+ (1,0) [0|4000] "m"  ADAS
 SG_ Ego_Lane_NextSpeedLimit_Type_2 : 89|2@1+ (1,0) [0|3] ""  ADAS
 SG_ Ego_Lane_NextSpeedLimit_Value_3 : 91|5@1+ (5,0) [0|130] "km/h"  ADAS
 SG_ Ego_Lane_NextSpeedLimit_Loc_3 : 96|12@1+ (1,0) [0|4000] "m"  ADAS
 SG_ Ego_Lane_NextSpeedLimit_Type_3 : 108|2@1+ (1,0) [0|3] ""  ADAS
 SG_ Ego_Lane_NextSpeedLimit_Value_4 : 110|5@1+ (5,0) [0|130] "km/h"  ADAS
 SG_ Ego_Lane_NextSpeedLimit_Loc_4 : 115|12@1+ (1,0) [0|4000] "m"  ADAS
 SG_ Ego_Lane_NextSpeedLimit_Type_4 : 127|2@1+ (1,0) [0|3] ""  ADAS
 SG_ Ego_Lane_NextTopoLocation_1 : 129|11@1+ (1,0) [0|2000] "m"  ADAS
 SG_ Ego_Lane_NextTopoType_1 : 140|3@1+ (1,0) [0|6] ""  ADAS
 SG_ Ego_Lane_NextTopoSide_1 : 143|1@1+ (1,0) [0|1] ""  ADAS
 SG_ Ego_Lane_NextTopoLocation_2 : 144|11@1+ (1,0) [0|2000] "m"  ADAS
 SG_ Ego_Lane_NextTopoType_2 : 155|3@1+ (1,0) [0|6] ""  ADAS
 SG_ Ego_Lane_NextTopoSide_2 : 158|1@1+ (1,0) [0|1] ""  ADAS
 SG_ Ego_Lane_NextTopoLocation_3 : 159|11@1+ (1,0) [0|2000] "m"  ADAS
 SG_ Ego_Lane_NextTopoType_3 : 170|3@1+ (1,0) [0|6] ""  ADAS
 SG_ Ego_Lane_NextTopoSide_3 : 173|1@1+ (1,0) [0|1] ""  ADAS
 SG_ Ego_Lane_NextTopoLocation_4 : 174|11@1+ (1,0) [0|2000] "m"  ADAS
 SG_ Ego_Lane_NextTopoType_4 : 185|3@1+ (1,0) [0|6] ""  ADAS
 SG_ Ego_Lane_NextTopoSide_4 : 188|1@1+ (1,0) [0|1] ""  ADAS
 SG_ Ego_Lane_CurrBoundary_Type_R : 189|5@1+ (1,0) [0|19] ""  ADAS
 SG_ Ego_Lane_NextBoundary_Loc_R_1 : 194|11@1+ (1,0) [0|2000] "m"  ADAS
 SG_ Ego_Lane_NextBoundary_Type_R_1 : 205|5@1+ (1,0) [0|19] ""  ADAS
 SG_ Ego_Lane_NextBoundary_Loc_R_2 : 210|11@1+ (1,0) [0|2000] "m"  ADAS
 SG_ Ego_Lane_NextBoundary_Type_R_2 : 221|5@1+ (1,0) [0|19] ""  ADAS
 SG_ Ego_Lane_NextBoundary_Loc_R_3 : 226|11@1+ (1,0) [0|2000] "m"  ADAS
 SG_ Ego_Lane_NextBoundary_Type_R_3 : 237|5@1+ (1,0) [0|19] ""  ADAS
 SG_ Ego_Lane_NextBoundary_Loc_R_4 : 242|11@1+ (1,0) [0|2000] "m"  ADAS
 SG_ Ego_Lane_NextBoundary_Type_R_4 : 253|5@1+ (1,0) [0|19] ""  ADAS
 SG_ Ego_Lane_CurrBoundary_Type_L : 258|5@1+ (1,0) [0|19] ""  ADAS
 SG_ Ego_Lane_NextBoundary_Loc_L_1 : 263|11@1+ (1,0) [0|2000] "m"  ADAS
 SG_ Ego_Lane_NextBoundary_Type_L_1 : 274|5@1+ (1,0) [0|19] ""  ADAS
 SG_ Ego_Lane_NextBoundary_Loc_L_2 : 279|11@1+ (1,0) [0|2000] "m"  ADAS
 SG_ Ego_Lane_NextBoundary_Type_L_2 : 290|5@1+ (1,0) [0|19] ""  ADAS
 SG_ Ego_Lane_NextBoundary_Loc_L_3 : 295|11@1+ (1,0) [0|2000] "m"  ADAS
 SG_ Ego_Lane_NextBoundary_Type_L_3 : 306|5@1+ (1,0) [0|19] ""  ADAS
 SG_ Ego_Lane_NextBoundary_Loc_L_4 : 311|11@1+ (1,0) [0|2000] "m"  ADAS
 SG_ Ego_Lane_NextBoundary_Type_L_4 : 322|5@1+ (1,0) [0|19] ""  ADAS

BO_ 1229 EHR_Ego_Lane_Info2_0x4CD: 64 EHR
 SG_ Ego_Lane_Info2_CRC : 0|16@1+ (1,0) [0|65535] ""  ADAS
 SG_ Ego_Lane_Info2_AliveCtr : 16|8@1+ (1,0) [0|255] ""  ADAS
 SG_ Ego_Lane_Info2_TimeStamp : 24|20@1+ (0.00065536,0) [0|687.194112] "s"  ADAS
 SG_ Ego_Lane_SpeedProfile_Near_N : 44|5@1+ (1,0) [0|31] ""  ADAS
 SG_ Ego_Lane_SpeedProfile_Near_00 : 49|7@1+ (2,0) [0|200] "km/h"  ADAS
 SG_ Ego_Lane_SpeedProfile_Near_01 : 56|7@1+ (2,0) [0|200] "km/h"  ADAS
 SG_ Ego_Lane_SpeedProfile_Near_02 : 63|7@1+ (2,0) [0|200] "km/h"  ADAS
 SG_ Ego_Lane_SpeedProfile_Near_03 : 70|7@1+ (2,0) [0|200] "km/h"  ADAS
 SG_ Ego_Lane_SpeedProfile_Near_04 : 77|7@1+ (2,0) [0|200] "km/h"  ADAS
 SG_ Ego_Lane_SpeedProfile_Near_05 : 84|7@1+ (2,0) [0|200] "km/h"  ADAS
 SG_ Ego_Lane_SpeedProfile_Near_06 : 91|7@1+ (2,0) [0|200] "km/h"  ADAS
 SG_ Ego_Lane_SpeedProfile_Near_07 : 98|7@1+ (2,0) [0|200] "km/h"  ADAS
 SG_ Ego_Lane_SpeedProfile_Near_08 : 105|7@1+ (2,0) [0|200] "km/h"  ADAS
 SG_ Ego_Lane_SpeedProfile_Near_09 : 112|7@1+ (2,0) [0|200] "km/h"  ADAS
 SG_ Ego_Lane_SpeedProfile_Near_10 : 119|7@1+ (2,0) [0|200] "km/h"  ADAS
 SG_ Ego_Lane_SpeedProfile_Near_11 : 126|7@1+ (2,0) [0|200] "km/h"  ADAS
 SG_ Ego_Lane_SpeedProfile_Near_12 : 133|7@1+ (2,0) [0|200] "km/h"  ADAS
 SG_ Ego_Lane_SpeedProfile_Near_13 : 140|7@1+ (2,0) [0|200] "km/h"  ADAS
 SG_ Ego_Lane_SpeedProfile_Near_14 : 147|7@1+ (2,0) [0|200] "km/h"  ADAS
 SG_ Ego_Lane_SpeedProfile_Near_15 : 154|7@1+ (2,0) [0|200] "km/h"  ADAS
 SG_ Ego_Lane_SpeedProfile_Near_16 : 161|7@1+ (2,0) [0|200] "km/h"  ADAS
 SG_ Ego_Lane_SpeedProfile_Near_17 : 168|7@1+ (2,0) [0|200] "km/h"  ADAS
 SG_ Ego_Lane_SpeedProfile_Near_18 : 175|7@1+ (2,0) [0|200] "km/h"  ADAS
 SG_ Ego_Lane_SpeedProfile_Near_19 : 182|7@1+ (2,0) [0|200] "km/h"  ADAS
 SG_ Ego_Lane_SpeedProfile_Near_20 : 189|7@1+ (2,0) [0|200] "km/h"  ADAS
 SG_ Ego_Lane_SpeedProfile_Near_21 : 196|7@1+ (2,0) [0|200] "km/h"  ADAS
 SG_ Ego_Lane_SpeedProfile_Near_22 : 203|7@1+ (2,0) [0|200] "km/h"  ADAS
 SG_ Ego_Lane_SpeedProfile_Far_N : 210|5@1+ (1,0) [0|31] ""  ADAS
 SG_ Ego_Lane_SpeedProfile_Far_00 : 215|7@1+ (2,0) [0|200] "km/h"  ADAS
 SG_ Ego_Lane_SpeedProfile_Far_01 : 222|7@1+ (2,0) [0|200] "km/h"  ADAS
 SG_ Ego_Lane_SpeedProfile_Far_02 : 229|7@1+ (2,0) [0|200] "km/h"  ADAS
 SG_ Ego_Lane_SpeedProfile_Far_03 : 236|7@1+ (2,0) [0|200] "km/h"  ADAS
 SG_ Ego_Lane_SpeedProfile_Far_04 : 243|7@1+ (2,0) [0|200] "km/h"  ADAS
 SG_ Ego_Lane_SpeedProfile_Far_05 : 250|7@1+ (2,0) [0|200] "km/h"  ADAS
 SG_ Ego_Lane_SpeedProfile_Far_06 : 257|7@1+ (2,0) [0|200] "km/h"  ADAS
 SG_ Ego_Lane_SpeedProfile_Far_07 : 264|7@1+ (2,0) [0|200] "km/h"  ADAS
 SG_ Ego_Lane_SpeedProfile_Far_08 : 271|7@1+ (2,0) [0|200] "km/h"  ADAS
 SG_ Ego_Lane_SpeedProfile_Far_09 : 278|7@1+ (2,0) [0|200] "km/h"  ADAS
 SG_ Ego_Lane_SpeedProfile_Far_10 : 285|7@1+ (2,0) [0|200] "km/h"  ADAS
 SG_ Ego_Lane_SpeedProfile_Far_11 : 292|7@1+ (2,0) [0|200] "km/h"  ADAS
 SG_ Ego_Lane_SpeedProfile_Far_12 : 299|7@1+ (2,0) [0|200] "km/h"  ADAS
 SG_ Ego_Lane_SpeedProfile_Far_13 : 306|7@1+ (2,0) [0|200] "km/h"  ADAS
 SG_ Ego_Lane_SpeedProfile_Far_14 : 313|7@1+ (2,0) [0|200] "km/h"  ADAS
 SG_ Ego_Lane_SpeedProfile_Far_15 : 320|7@1+ (2,0) [0|200] "km/h"  ADAS
 SG_ Ego_Lane_SpeedProfile_Far_16 : 327|7@1+ (2,0) [0|200] "km/h"  ADAS
 SG_ Ego_Lane_NextHotspot_Type_1 : 334|3@1+ (1,0) [0|3] ""  ADAS
 SG_ Ego_Lane_NextHotspot_Loc_1 : 337|11@1+ (1,0) [0|2000] "m"  ADAS
 SG_ Ego_Lane_NextHotspot_Length_1 : 348|8@1+ (10,0) [0|2000] "m"  ADAS
 SG_ Ego_Lane_NextHotspot_Int_1 : 356|6@1+ (0.015873,0) [0|1] ""  ADAS
 SG_ Ego_Lane_NextHotspot_Prob_1 : 362|8@1+ (0.00392157,0) [0|1] ""  ADAS
 SG_ Ego_Lane_NextHotspot_Side_1 : 370|1@1+ (1,0) [0|1] ""  ADAS
 SG_ Ego_Lane_NextHotspot_Type_2 : 371|3@1+ (1,0) [0|3] ""  ADAS
 SG_ Ego_Lane_NextHotspot_Loc_2 : 374|11@1+ (1,0) [0|2000] "m"  ADAS
 SG_ Ego_Lane_NextHotspot_Length_2 : 385|8@1+ (10,0) [0|2000] "m"  ADAS
 SG_ Ego_Lane_NextHotspot_Int_2 : 393|6@1+ (0.015873,0) [0|1] ""  ADAS
 SG_ Ego_Lane_NextHotspot_Prob_2 : 399|8@1+ (0.00392157,0) [0|1] ""  ADAS
 SG_ Ego_Lane_NextHotspot_Side_2 : 407|1@1+ (1,0) [0|1] ""  ADAS
 SG_ Ego_Lane_NextHotspot_Type_3 : 408|3@1+ (1,0) [0|3] ""  ADAS
 SG_ Ego_Lane_NextHotspot_Loc_3 : 411|11@1+ (1,0) [0|2000] "m"  ADAS
 SG_ Ego_Lane_NextHotspot_Length_3 : 422|8@1+ (10,0) [0|2000] "m"  ADAS
 SG_ Ego_Lane_NextHotspot_Int_3 : 430|6@1+ (0.015873,0) [0|1] ""  ADAS
 SG_ Ego_Lane_NextHotspot_Prob_3 : 436|8@1+ (0.00392157,0) [0|1] ""  ADAS
 SG_ Ego_Lane_NextHotspot_Side_3 : 444|1@1+ (1,0) [0|1] ""  ADAS
 SG_ Ego_Lane_NextHotspot_Type_4 : 445|3@1+ (1,0) [0|3] ""  ADAS
 SG_ Ego_Lane_NextHotspot_Loc_4 : 448|11@1+ (1,0) [0|2000] "m"  ADAS
 SG_ Ego_Lane_NextHotspot_Length_4 : 459|8@1+ (10,0) [0|2000] "m"  ADAS
 SG_ Ego_Lane_NextHotspot_Int_4 : 467|6@1+ (0.015873,0) [0|1] ""  ADAS
 SG_ Ego_Lane_NextHotspot_Prob_4 : 473|8@1+ (0.00392157,0) [0|1] ""  ADAS
 SG_ Ego_Lane_NextHotspot_Side_4 : 481|1@1+ (1,0) [0|1] ""  ADAS

BO_ 1230 EHR_Left_Lane_info_0x4CE: 48 EHR
 SG_ Left_Lane_Info_CRC : 0|16@1+ (1,0) [0|65535] ""  ADAS
 SG_ Left_Lane_Info_AliveCtr : 16|8@1+ (1,0) [0|255] ""  ADAS
 SG_ Left_Lane_Info_TimeStamp : 24|20@1+ (0.00065536,0) [0|687.194112] "s"  ADAS
 SG_ Left_Lane_Exists : 44|1@1+ (1,0) [0|1] ""  ADAS
 SG_ Left_Lane_isOvertakeLane : 45|1@1+ (1,0) [0|1] ""  ADAS
 SG_ Left_Lane_Start_dx : 46|12@1+ (1,0) [0|4000] ""  ADAS
 SG_ Left_CurrentSpeedLimit : 58|5@1+ (5,0) [0|130] "km/h"  ADAS
 SG_ Left_CurrentSpeedLimit_Type : 63|2@1+ (1,0) [0|3] ""  ADAS
 SG_ Left_NextSpeedLimit_Value_1 : 65|5@1+ (5,0) [0|130] "km/h"  ADAS
 SG_ Left_NextSpeedLimit_Location_1 : 70|12@1+ (1,0) [0|4000] "m"  ADAS
 SG_ Left_NextSpeedLimit_Type_1 : 82|2@1+ (1,0) [0|3] ""  ADAS
 SG_ Left_NextSpeedLimit_Value_2 : 84|5@1+ (5,0) [0|130] "km/h"  ADAS
 SG_ Left_NextSpeedLimit_Location_2 : 89|12@1+ (1,0) [0|4000] "m"  ADAS
 SG_ Left_NextSpeedLimit_Type_2 : 101|2@1+ (1,0) [0|3] ""  ADAS
 SG_ Left_NextSpeedLimit_Value_3 : 103|5@1+ (5,0) [0|130] "km/h"  ADAS
 SG_ Left_NextSpeedLimit_Location_3 : 108|12@1+ (1,0) [0|4000] "m"  ADAS
 SG_ Left_NextSpeedLimit_Type_3 : 120|2@1+ (1,0) [0|3] ""  ADAS
 SG_ Left_NextSpeedLimit_Value_4 : 122|5@1+ (5,0) [0|130] "km/h"  ADAS
 SG_ Left_NextSpeedLimit_Location_4 : 127|12@1+ (1,0) [0|4000] "m"  ADAS
 SG_ Left_NextSpeedLimit_Type_4 : 139|2@1+ (1,0) [0|3] ""  ADAS
 SG_ Left_SpeedProfile_Far_N : 141|5@1+ (1,0) [0|31] ""  ADAS
 SG_ Left_SpeedProfile_Far_00 : 146|7@1+ (2,0) [0|200] "km/h"  ADAS
 SG_ Left_SpeedProfile_Far_01 : 153|7@1+ (2,0) [0|200] "km/h"  ADAS
 SG_ Left_SpeedProfile_Far_02 : 160|7@1+ (2,0) [0|200] "km/h"  ADAS
 SG_ Left_SpeedProfile_Far_03 : 167|7@1+ (2,0) [0|200] "km/h"  ADAS
 SG_ Left_SpeedProfile_Far_04 : 174|7@1+ (2,0) [0|200] "km/h"  ADAS
 SG_ Left_SpeedProfile_Far_05 : 181|7@1+ (2,0) [0|200] "km/h"  ADAS
 SG_ Left_SpeedProfile_Far_06 : 188|7@1+ (2,0) [0|200] "km/h"  ADAS
 SG_ Left_SpeedProfile_Far_07 : 195|7@1+ (2,0) [0|200] "km/h"  ADAS
 SG_ Left_SpeedProfile_Far_08 : 202|7@1+ (2,0) [0|200] "km/h"  ADAS
 SG_ Left_SpeedProfile_Far_09 : 209|7@1+ (2,0) [0|200] "km/h"  ADAS
 SG_ Left_SpeedProfile_Far_10 : 216|7@1+ (2,0) [0|200] "km/h"  ADAS
 SG_ Left_SpeedProfile_Far_11 : 223|7@1+ (2,0) [0|200] "km/h"  ADAS
 SG_ Left_SpeedProfile_Far_12 : 230|7@1+ (2,0) [0|200] "km/h"  ADAS
 SG_ Left_SpeedProfile_Far_13 : 237|7@1+ (2,0) [0|200] "km/h"  ADAS
 SG_ Left_SpeedProfile_Far_14 : 244|7@1+ (2,0) [0|200] "km/h"  ADAS
 SG_ Left_SpeedProfile_Far_15 : 251|7@1+ (2,0) [0|200] "km/h"  ADAS
 SG_ Left_SpeedProfile_Far_16 : 258|7@1+ (2,0) [0|200] "km/h"  ADAS
 SG_ Left_NextTopo_Loc_1 : 265|11@1+ (1,0) [0|2000] "m"  ADAS
 SG_ Left_NextTopo_Type_1 : 276|3@1+ (1,0) [0|6] ""  ADAS
 SG_ Left_NextTopo_Side_1 : 279|1@1+ (1,0) [0|1] ""  ADAS
 SG_ Left_NextTopo_Loc_2 : 280|11@1+ (1,0) [0|2000] "m"  ADAS
 SG_ Left_NextTopo_Type_2 : 291|3@1+ (1,0) [0|6] ""  ADAS
 SG_ Left_NextTopo_Side_2 : 294|1@1+ (1,0) [0|1] ""  ADAS
 SG_ Left_NextTopo_Loc_3 : 295|11@1+ (1,0) [0|2000] "m"  ADAS
 SG_ Left_NextTopo_Type_3 : 306|3@1+ (1,0) [0|6] ""  ADAS
 SG_ Left_NextTopo_Side_3 : 309|1@1+ (1,0) [0|1] ""  ADAS
 SG_ Left_NextTopo_Loc_4 : 310|11@1+ (1,0) [0|2000] "m"  ADAS
 SG_ Left_NextTopo_Type_4 : 321|3@1+ (1,0) [0|6] ""  ADAS
 SG_ Left_NextTopo_Side_4 : 324|1@1+ (1,0) [0|1] ""  ADAS

BO_ 1231 EHR_Right_Lane_info_0x4CF: 48 EHR
 SG_ Right_Lane_Info_CRC : 0|16@1+ (1,0) [0|65535] ""  ADAS
 SG_ Right_Lane_Info_AliveCtr : 16|8@1+ (1,0) [0|255] ""  ADAS
 SG_ Right_Lane_Info_TimeStamp : 24|20@1+ (0.00065536,0) [0|687.194112] "s"  ADAS
 SG_ Right_Lane_Exists : 44|1@1+ (1,0) [0|1] ""  ADAS
 SG_ Right_Lane_isOvertakeLane : 45|1@1+ (1,0) [0|1] ""  ADAS
 SG_ Right_Lane_Start_dx : 46|12@1+ (1,0) [0|4000] ""  ADAS
 SG_ Right_CurrentSpeedLimit : 58|5@1+ (5,0) [0|130] "km/h"  ADAS
 SG_ Right_CurrentSpeedLimit_Type : 63|2@1+ (1,0) [0|3] ""  ADAS
 SG_ Right_NextSpeedLimit_Value_1 : 65|5@1+ (5,0) [0|130] "km/h"  ADAS
 SG_ Right_NextSpeedLimit_Location_1 : 70|12@1+ (1,0) [0|4000] "m"  ADAS
 SG_ Right_NextSpeedLimit_Type_1 : 82|2@1+ (1,0) [0|1] ""  ADAS
 SG_ Right_NextSpeedLimit_Value_2 : 84|5@1+ (5,0) [0|130] "km/h"  ADAS
 SG_ Right_NextSpeedLimit_Location_2 : 89|12@1+ (1,0) [0|4000] "m"  ADAS
 SG_ Right_NextSpeedLimit_Type_2 : 101|2@1+ (1,0) [0|3] ""  ADAS
 SG_ Right_NextSpeedLimit_Value_3 : 103|5@1+ (5,0) [0|130] "km/h"  ADAS
 SG_ Right_NextSpeedLimit_Location_3 : 108|12@1+ (1,0) [0|4000] "m"  ADAS
 SG_ Right_NextSpeedLimit_Type_3 : 120|2@1+ (1,0) [0|3] ""  ADAS
 SG_ Right_NextSpeedLimit_Value_4 : 122|5@1+ (5,0) [0|130] "km/h"  ADAS
 SG_ Right_NextSpeedLimit_Location_4 : 127|12@1+ (1,0) [0|4000] "m"  ADAS
 SG_ Right_NextSpeedLimit_Type_4 : 139|2@1+ (1,0) [0|3] ""  ADAS
 SG_ Right_SpeedProfile_Far_N : 141|5@1+ (1,0) [0|31] ""  ADAS
 SG_ Right_SpeedProfile_Far_00 : 146|7@1+ (2,0) [0|200] "km/h"  ADAS
 SG_ Right_SpeedProfile_Far_01 : 153|7@1+ (2,0) [0|200] "km/h"  ADAS
 SG_ Right_SpeedProfile_Far_02 : 160|7@1+ (2,0) [0|200] "km/h"  ADAS
 SG_ Right_SpeedProfile_Far_03 : 167|7@1+ (2,0) [0|200] "km/h"  ADAS
 SG_ Right_SpeedProfile_Far_04 : 174|7@1+ (2,0) [0|200] "km/h"  ADAS
 SG_ Right_SpeedProfile_Far_05 : 181|7@1+ (2,0) [0|200] "km/h"  ADAS
 SG_ Right_SpeedProfile_Far_06 : 188|7@1+ (2,0) [0|200] "km/h"  ADAS
 SG_ Right_SpeedProfile_Far_07 : 195|7@1+ (2,0) [0|200] "km/h"  ADAS
 SG_ Right_SpeedProfile_Far_08 : 202|7@1+ (2,0) [0|200] "km/h"  ADAS
 SG_ Right_SpeedProfile_Far_09 : 209|7@1+ (2,0) [0|200] "km/h"  ADAS
 SG_ Right_SpeedProfile_Far_10 : 216|7@1+ (2,0) [0|200] "km/h"  ADAS
 SG_ Right_SpeedProfile_Far_11 : 223|7@1+ (2,0) [0|200] "km/h"  ADAS
 SG_ Right_SpeedProfile_Far_12 : 230|7@1+ (2,0) [0|200] "km/h"  ADAS
 SG_ Right_SpeedProfile_Far_13 : 237|7@1+ (2,0) [0|200] "km/h"  ADAS
 SG_ Right_SpeedProfile_Far_14 : 244|7@1+ (2,0) [0|200] "km/h"  ADAS
 SG_ Right_SpeedProfile_Far_15 : 251|7@1+ (2,0) [0|200] "km/h"  ADAS
 SG_ Right_SpeedProfile_Far_16 : 258|7@1+ (2,0) [0|200] "km/h"  ADAS
 SG_ Right_NextTopo_Loc_1 : 265|11@1+ (1,0) [0|2000] "m"  ADAS
 SG_ Right_NextTopo_Type_1 : 276|3@1+ (1,0) [0|6] ""  ADAS
 SG_ Right_NextTopo_Side_1 : 279|1@1+ (1,0) [0|1] ""  ADAS
 SG_ Right_NextTopo_Loc_2 : 280|11@1+ (1,0) [0|2000] "m"  ADAS
 SG_ Right_NextTopo_Type_2 : 291|3@1+ (1,0) [0|6] ""  ADAS
 SG_ Right_NextTopo_Side_2 : 294|1@1+ (1,0) [0|1] ""  ADAS
 SG_ Right_NextTopo_Loc_3 : 295|11@1+ (1,0) [0|2000] "m"  ADAS
 SG_ Right_NextTopo_Type_3 : 306|3@1+ (1,0) [0|6] ""  ADAS
 SG_ Right_NextTopo_Side_3 : 309|1@1+ (1,0) [0|1] ""  ADAS
 SG_ Right_NextTopo_Loc_4 : 310|11@1+ (1,0) [0|2000] "m"  ADAS
 SG_ Right_NextTopo_Type_4 : 321|3@1+ (1,0) [0|6] ""  ADAS
 SG_ Right_NextTopo_Side_4 : 324|1@1+ (1,0) [0|1] ""  ADAS

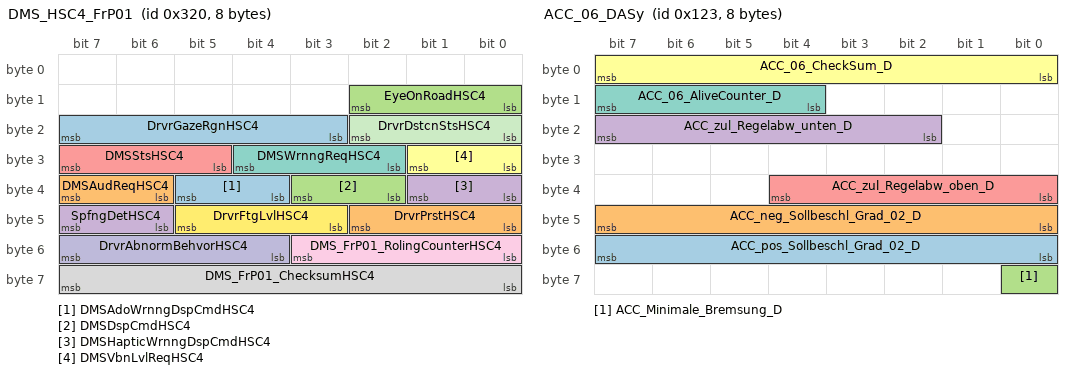
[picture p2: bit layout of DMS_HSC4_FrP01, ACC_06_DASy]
BO_ 800 DMS_HSC4_FrP01: 8 DMS
 SG_ DMSAdoWrnngDspCmdHSC4 : 37|2@0+ (1,0) [0|3] ""  ADAS
 SG_ DMSAudReqHSC4 : 39|2@0+ (1,0) [0|3] ""  ADAS
 SG_ DMSDspCmdHSC4 : 35|2@0+ (1,0) [0|3] ""  ADAS
 SG_ DMSHapticWrnngDspCmdHSC4 : 33|2@0+ (1,0) [0|3] ""  ADAS
 SG_ DMSStsHSC4 : 31|3@0+ (1,0) [0|7] ""  ADAS
 SG_ DMSVbnLvlReqHSC4 : 25|2@0+ (1,0) [0|3] ""  ADAS
 SG_ DMSWrnngReqHSC4 : 28|3@0+ (1,0) [0|7] ""  ADAS
 SG_ DMS_FrP01_ChecksumHSC4 : 63|8@0+ (1,0) [0|255] ""  ADAS
 SG_ DMS_FrP01_RolingCounterHSC4 : 51|4@0+ (1,0) [0|15] "count value"  ADAS
 SG_ DrvrAbnormBehvorHSC4 : 55|4@0+ (1,0) [0|15] ""  ADAS
 SG_ DrvrDstcnStsHSC4 : 18|3@0+ (1,0) [0|7] ""  ADAS
 SG_ DrvrFtgLvlHSC4 : 45|3@0+ (1,0) [0|7] ""  ADAS
 SG_ DrvrGazeRgnHSC4 : 23|5@0+ (1,0) [0|31] ""  ADAS
 SG_ DrvrPrstHSC4 : 42|3@0+ (1,0) [0|7] ""  ADAS
 SG_ EyeOnRoadHSC4 : 10|3@0+ (1,0) [0|7] ""  ADAS
 SG_ SpfngDetHSC4 : 47|2@0+ (1,0) [0|3] ""  ADAS

BO_ 453 EPS2ADAS_0x1C5: 12 HASy
 SG_ ADAS_1C5_CheckSum : 7|8@0+ (1,0) [0|255] ""  ADAS
 SG_ ADAS_1C5_AliveCounter : 11|4@0+ (1,0) [0|15] ""  ADAS
 SG_ EPS_ActRoadWheelAngValue : 23|16@0+ (0.005,-45) [-45|45] "degree"  ADAS
 SG_ EPS_ActRPCTrq : 39|11@0+ (0.02,-20.48) [-20.48|20.46] "Nm"  ADAS
 SG_ EPS_LatDrvLvl12SrvAvl : 44|2@0+ (1,0) [0|3] ""  ADAS
 SG_ EPS_IntRPCMaxTrq : 42|11@0+ (0.02,-20.48) [-20.48|20.46] "Nm"  ADAS
 SG_ EPS_IntRPCMinTrq : 63|11@0+ (0.02,-20.48) [-20.48|20.46] "Nm"  ADAS
 SG_ EPS_LatMCHptcWrnSrvAvl : 68|2@0+ (1,0) [0|3] ""  ADAS
 SG_ EPS_ActRoadWheelAngState : 66|2@0+ (1,0) [0|3] ""  ADAS
 SG_ EPS_LatMCRoadWheelAngActive : 64|1@0+ (1,0) [0|1] ""  ADAS

BO_ 1210 ADAS_0x4BA_HMI: 64 ADAS
 SG_ ACC_ICON_LADI : 312|2@1+ (1,0) [0|3] ""  HASy
 SG_ ADAS_4BA_CheckSum : 0|16@1+ (1,0) [0|65535] ""  HASy
 SG_ EgoDistanceToRightLaneMarking : 103|7@1- (0.06,0) [-3.84|3.78] "m"  HASy
 SG_ CurvatureInformation : 110|8@1- (25,0) [-3200|3175] "m"  HASy
 SG_ TrafficSignSpeedLimit : 118|5@1+ (5,0) [0|150] "kph"  HASy
 SG_ SensorConeRearLeft : 123|2@1+ (1,0) [0|3] ""  HASy
 SG_ SensorConeRearRight : 125|2@1+ (1,0) [0|3] ""  HASy
 SG_ SensorConeFrontLeft : 127|2@1+ (1,0) [0|3] ""  HASy
 SG_ SensorConeFrontRight : 129|2@1+ (1,0) [0|3] ""  HASy
 SG_ SensorConeFrontCenter : 131|2@1+ (1,0) [0|3] ""  HASy
 SG_ NeighboringVehicle1VehicleType : 133|3@1+ (1,0) [0|7] ""  HASy
 SG_ NeighboringVehicle1X : 136|8@1+ (1.2,-50.4) [-50.4|255.6] "m"  HASy
 SG_ NeighboringVehicle1Y : 144|8@1- (0.06,0) [-7.68|7.62] "m"  HASy
 SG_ NeighboringVehicle1AugmentedData : 154|3@1+ (1,0) [0|7] ""  HASy
 SG_ NeighboringVehicle2VehicleType : 157|3@1+ (1,0) [0|7] ""  HASy
 SG_ NeighboringVehicle2X : 160|8@1+ (1.2,-50.4) [-50.4|255.6] "m"  HASy
 SG_ NeighboringVehicle2Y : 168|8@1- (0.06,0) [-7.68|7.62] "m"  HASy
 SG_ ADAS_4BA_AliveCounter : 16|8@1+ (1,0) [0|255] ""  HASy
 SG_ NeighboringVehicle2AugmentedData : 176|3@1+ (1,0) [0|7] ""  HASy
 SG_ NeighboringVehicle3VehicleType : 179|3@1+ (1,0) [0|7] ""  HASy
 SG_ NeighboringVehicle3X : 182|8@1+ (1.2,-50.4) [-50.4|255.6] "m"  HASy
 SG_ NeighboringVehicle3Y : 190|8@1- (0.06,0) [-7.68|7.62] "m"  HASy
 SG_ NeighboringVehicle3AugmentedData : 198|3@1+ (1,0) [0|7] ""  HASy
 SG_ NeighboringVehicle4VehicleType : 201|3@1+ (1,0) [0|7] ""  HASy
 SG_ NeighboringVehicle4X : 204|8@1+ (1.2,-50.4) [-50.4|255.6] "m"  HASy
 SG_ NeighboringVehicle4Y : 212|8@1- (0.06,0) [-7.68|7.62] "m"  HASy
 SG_ NeighboringVehicle4AugmentedData : 220|3@1+ (1,0) [0|7] ""  HASy
 SG_ NeighboringVehicle5VehicleType : 223|3@1+ (1,0) [0|7] ""  HASy
 SG_ NeighboringVehicle5X : 226|8@1+ (1.2,-50.4) [-50|250] "m"  HASy
 SG_ NeighboringVehicle5Y : 234|8@1- (0.06,0) [-7.68|7.62] "m"  HASy
 SG_ NeighboringVehicle5AugmentedData : 242|3@1+ (1,0) [0|7] ""  HASy
 SG_ NeighboringVehicle6VehicleType : 245|3@1+ (1,0) [0|7] ""  HASy
 SG_ NeighboringVehicle6X : 248|8@1+ (1.2,-50.4) [-50|250] "m"  HASy
 SG_ LedHadState : 24|4@1+ (1,0) [0|15] ""  HASy
 SG_ NeighboringVehicle6Y : 256|8@1- (0.06,0) [-7.68|7.62] "m"  HASy
 SG_ NeighboringVehicle6AugmentedData : 264|3@1+ (1,0) [0|7] ""  HASy
 SG_ NeighboringVehicle7VehicleType : 267|3@1+ (1,0) [0|7] ""  HASy
 SG_ NeighboringVehicle7X : 270|8@1+ (1.2,-50.4) [-50|250] "m"  HASy
 SG_ NeighboringVehicle7Y : 278|8@1- (0.06,0) [-7.68|7.62] "m"  HASy
 SG_ NeighboringVehicle7AugmentedData : 286|3@1+ (1,0) [0|7] ""  HASy
 SG_ NeighboringVehicle8VehicleType : 289|3@1+ (1,0) [0|7] ""  HASy
 SG_ HwaHfStatus : 28|3@1+ (1,0) [0|7] ""  HASy
 SG_ NeighboringVehicle8X : 292|8@1+ (1.2,-50.4) [-50.4|255.6] "m"  HASy
 SG_ NeighboringVehicle8Y : 300|8@1- (0.06,0) [-7.68|7.62] "m"  HASy
 SG_ NeighboringVehicle8AugmentedData : 308|3@1+ (1,0) [0|7] ""  HASy
 SG_ HwaHonStatus : 31|3@1+ (1,0) [0|7] ""  HASy
 SG_ HwaAccStatus : 34|3@1+ (1,0) [0|7] ""  HASy
 SG_ SetSpeed : 37|8@1+ (1,0) [0|255] "kph"  HASy
 SG_ SetSpeedColor : 45|3@1+ (1,0) [0|7] ""  HASy
 SG_ DisplayedEgoSpeed : 48|8@1+ (1,0) [0|255] "kph"  HASy
 SG_ DisplayedEgoSpeedColor : 56|3@1+ (1,0) [0|7] ""  HASy
 SG_ DisplayedLaneMarkingLeftType : 59|2@1+ (1,0) [0|3] ""  HASy
 SG_ DisplayedLaneMarkingLeftColor : 61|3@1+ (1,0) [0|7] ""  HASy
 SG_ DisplayedLaneMarkingRightType : 64|2@1+ (1,0) [0|3] ""  HASy
 SG_ DisplayedLaneMarkingRightColor : 66|3@1+ (1,0) [0|7] ""  HASy
 SG_ TimeGapSetValue : 69|3@1+ (1,0) [0|7] ""  HASy
 SG_ TimeGapColor : 72|3@1+ (1,0) [0|7] ""  HASy
 SG_ EgoLaneChange : 75|3@1+ (1,0) [0|7] ""  HASy
 SG_ DisplayedTextMessageId : 78|6@1+ (1,0) [0|63] ""  HASy
 SG_ PopupTextMessage : 84|2@1+ (1,0) [0|3] ""  HASy
 SG_ AudioNotificationId : 86|4@1+ (1,0) [0|15] ""  HASy
 SG_ AuxiliarySymbol : 90|4@1+ (1,0) [0|15] ""  HASy
 SG_ EgoLaneAssignment : 94|2@1+ (1,0) [0|3] ""  HASy
 SG_ EgoDistanceToLeftLaneMarking : 96|7@1- (0.06,0) [-3.84|3.78] "m"  HASy

BO_ 291 ACC_06_DASy: 8 ADAS
 SG_ ACC_pos_Sollbeschl_Grad_02_D : 55|8@0+ (0.05,0) [0|12.75] "Unit_MeterPerCubicSecon"  HASy
 SG_ ACC_neg_Sollbeschl_Grad_02_D : 47|8@0+ (0.05,0) [0|12.75] "Unit_MeterPerCubicSecon"  HASy
 SG_ ACC_Minimale_Bremsung_D : 56|1@0+ (1,0) [0|1] ""  HASy
 SG_ ACC_zul_Regelabw_unten_D : 23|6@0+ (0.024,0) [0|1.512] "Unit_MeterPerSeconSquar"  HASy
 SG_ ACC_zul_Regelabw_oben_D : 36|5@0+ (0.0625,0) [0|1.9375] "Unit_MeterPerSeconSquar"  HASy
 SG_ ACC_06_CheckSum_D : 7|8@0+ (1,0) [0|255] ""  HASy
 SG_ ACC_06_AliveCounter_D : 15|4@0+ (1,0) [0|15] ""  HASy

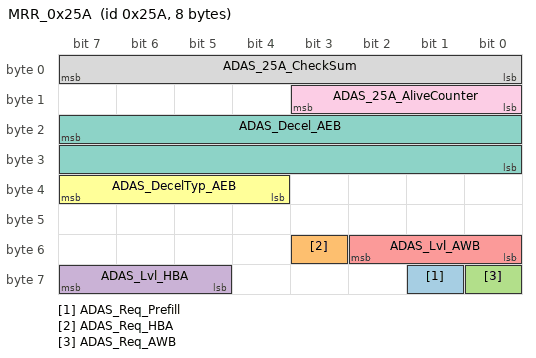
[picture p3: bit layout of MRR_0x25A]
BO_ 602 MRR_0x25A: 8 ADAS
 SG_ ADAS_Req_Prefill : 57|1@0+ (1,0) [0|1] ""  GWS
 SG_ ADAS_Req_HBA : 51|1@0+ (1,0) [0|1] ""  GWS
 SG_ ADAS_Req_AWB : 56|1@0+ (1,0) [0|1] ""  GWS
 SG_ ADAS_Lvl_HBA : 63|3@0+ (1,0) [0|7] ""  GWS
 SG_ ADAS_Lvl_AWB : 50|3@0+ (1,0) [0|7] ""  GWS
 SG_ ADAS_DecelTyp_AEB : 39|4@0+ (1,0) [0|15] ""  GWS
 SG_ ADAS_Decel_AEB : 23|16@0+ (0.0004882,-16) [-16|15.994187] "m/s²"  GWS
 SG_ ADAS_25A_CheckSum : 7|8@0+ (1,0) [0|255] ""  GWS
 SG_ ADAS_25A_AliveCounter : 11|4@0+ (1,0) [0|15] ""  GWS

BO_ 1554 HandoverIndication: 1 HASy
 SG_ HandoverIndication : 0|2@1+ (1,0) [0|3] ""  ADAS

BO_TX_BU_ 601 : MRR_M,MRR;

CM_ BU_ VIC "Visualization Computer";
CM_ BU_ GWS "Gateway Safety (AEB)";
CM_ BU_ HASy "HAD Safety Gateway";
CM_ BO_ 3221225472 "This is a message for not used signals, created by Vector CANdb++ DBC OLE DB Provider.";
CM_ SG_ 3221225472 GRA_ACC_01_CRC "For MLB:
'Berechnung siehe Lastenheft 'Kommunikationsabsicherung für FlexRay und CAN''
Ab MQB und MLBevo:
'Berechnung siehe Lastenheft 'End-to-End Kommunikationsabsicherung''
Endwerte siehe Begleitdokument 'S-PDU Kennungsfolgen'";
CM_ BO_ 443 "AFB: Actuator Feedback";
CM_ SG_ 443 AFB_1BB_AliveCounter "overtaken from

VCU_1BA_±¨ÎÄ¼ÆÊýÆ÷
VCU_1BA_AliveCounter";
CM_ SG_ 443 AFB_1BB_CheckSum "overtaken from

VCU_1BA_±¨ÎÄÐ£ÑéºÍ(0x75)
VCU_1BA_CheckSum";
CM_ SG_ 601 ADAS_Req_Prefill "Prefill??";
CM_ SG_ 601 ADAS_Req_HBA "HBA??";
CM_ SG_ 601 ADAS_Req_AWB "AWB??";
CM_ SG_ 601 ADAS_Lvl_HBA "HBA??";
CM_ SG_ 601 ADAS_Lvl_AWB "AWB??";
CM_ SG_ 601 ADAS_DecelTyp_AEB "AEB?????";
CM_ SG_ 601 ADAS_Decel_AEB "AEB???";
CM_ SG_ 601 ADAS_259_CheckSum "ADAS_259_?????(0x51)
ADAS_259_CheckSum
";
CM_ SG_ 601 ADAS_259_AliveCounter "ADAS_259_?????
ADAS_259_AliveCounter";
CM_ SG_ 716 HODTchZone1Val_h8HSC8 "Hod Touch Zone 1 Value";
CM_ SG_ 449 DADCSteerTqReqActive "DADC request flag for Hands-on/Hands-Free steering torque control to be enabled";
CM_ SG_ 449 ADAS_1C1_CheckSum "ADAS_1C1_CheckSum";
CM_ SG_ 449 ADAS_RdWhlAgReqActive "DASy request flag for road wheel angle control to be enabled";
CM_ SG_ 449 ADAS_1C1_AliveCounter "ADAS_1C1_AliveCounter";
CM_ SG_ 449 ADAS_RdWhlAgReq "DASy send road wheel angle request to EPS";
CM_ SG_ 449 ADAS_ExtMaxRPCTrq "Maximum externally allowed RPC torque for Level 2 (TBT Level)";
CM_ SG_ 449 ADAS_ExtMinRPCTrq "Minimum externally allowed RPC torque for Level 2 (TBT Level)";
CM_ SG_ 1216 GF_map_position_accuracy "Standard deviation of the offset";
CM_ SG_ 1216 GF_map_position_deviation "Distance between map matched position and estimated position";
CM_ SG_ 1216 GF_CRC "CRC - Autosar E2E Profile 5";
CM_ SG_ 1216 GF_AliveCtr "Alive counter - Autosar E2E Profile 5";
CM_ SG_ 1216 GF_Currentlane_Index "Position-->currentlaneindex";
CM_ SG_ 1216 GF_NumberOfLanes "Position-->NumberOfLanePerDirection in current path";
CM_ SG_ 1216 GF_Region_outOfODD_offset "Offset to the nearest  upcoming out of ODD  region for the current path";
CM_ SG_ 1216 GF_Country_outOfODD_offset "Offset to the nearest  upcoming out of ODD  country for the current path";
CM_ SG_ 1216 GF_LaneTrans_outOfODD_offset "Offset to the nearest  upcoming out of ODD  lane transition for the current path";
CM_ SG_ 1216 GF_Curvature_outOfODD_offset "Offset to point in the lane at which the curve radius is below minViableRoadRadius";
CM_ SG_ 1216 GF_LaneType_outOfODD_offset "Offset to the nearest  upcoming  out of ODD lane type of the current path";
CM_ SG_ 1216 GF_RoadSlope_outOfODD_offset "Offset to point in the road at which the road slope is below minRoadSlope or above maxRoadSlope.";
CM_ SG_ 1216 GF_LaneWidth_outOfODD_offset "Offset to point in the lane at which the lane width is below the minLaneWidth threshold";
CM_ SG_ 1216 GF_FormOfWay_outOfODD_offset "Offset to the nearest  upcoming  out of ODD  form of way (road class) for the current path";
CM_ SG_ 1216 GF_MapExpired "True if the map data is older than maxMapAge. False otherwise.";
CM_ SG_ 1216 GF_BlackListedSegment_offset "Offset to the nearest  upcoming out black listed segment for the current path";
CM_ SG_ 1216 GF_Intersection_offset "Offset to the nearest  upcoming intersection for the current path";
CM_ SG_ 1216 GF_SideWind_offset "Offset to the nearest  upcoming side wind sign  for the current path";
CM_ SG_ 1216 GF_ActiveSpeedLimit "Current speed limit";
CM_ SG_ 1216 GF_TollGate_offset "Offset to the nearest  upcoming tollgate  for the current path";
CM_ SG_ 1216 GF_TrafficLight_offset "Offset to the nearest  upcoming traffic light  for the current path";
CM_ SG_ 1216 GF_Tunnel_Offset "Offset to the nearest  upcoming tunnel for the current path";
CM_ SG_ 1216 GF_MapStatus "This enumeration defines values for the Map Status. These values are not mutually exclusive and they are intended to be used as a bitmask obtained by an OR of all values.";
CM_ SG_ 1217 Cv_CRC "CRC - Autosar E2E Profile 5";
CM_ SG_ 1217 Cv_AliveCtr "Alive counter - Autosar E2E Profile 5";
CM_ SG_ 1217 Cv_Value_Seg00 "Absolute value of curvature at the segment";
CM_ SG_ 1217 Cv_Value_Seg01 "Absolute value of curvature at the segment";
CM_ SG_ 1217 Cv_Value_Seg02 "Absolute value of curvature at the segment";
CM_ SG_ 1217 Cv_Value_Seg03 "Absolute value of curvature at the segment";
CM_ SG_ 1217 Cv_Value_Seg04 "Absolute value of curvature at the segment";
CM_ SG_ 1217 Cv_Value_Seg05 "Absolute value of curvature at the segment";
CM_ SG_ 1217 Cv_Value_Seg06 "Absolute value of curvature at the segment";
CM_ SG_ 1217 Cv_Value_Seg07 "Absolute value of curvature at the segment";
CM_ SG_ 1217 Cv_Value_Seg08 "Absolute value of curvature at the segment";
CM_ SG_ 1217 Cv_Value_Seg09 "Absolute value of curvature at the segment";
CM_ SG_ 1217 Cv_Value_Seg10 "Absolute value of curvature at the segment";
CM_ SG_ 1217 Cv_Value_Seg11 "Absolute value of curvature at the segment";
CM_ SG_ 1217 Cv_Value_Seg12 "Absolute value of curvature at the segment";
CM_ SG_ 1217 Cv_Value_Seg13 "Absolute value of curvature at the segment";
CM_ SG_ 1217 Cv_Value_Seg14 "Absolute value of curvature at the segment";
CM_ SG_ 1217 Cv_Value_Seg15 "Absolute value of curvature at the segment";
CM_ SG_ 1217 Cv_Value_Seg16 "Absolute value of curvature at the segment";
CM_ SG_ 1217 Cv_Value_Seg17 "Absolute value of curvature at the segment";
CM_ SG_ 1217 Cv_Value_Seg18 "Absolute value of curvature at the segment";
CM_ SG_ 1217 Cv_Value_Seg19 "Absolute value of curvature at the segment";
CM_ SG_ 1217 Cv_Offset_Seg00 "Offset of the curvature value at the segment";
CM_ SG_ 1217 Cv_Offset_Seg01 "Offset of the curvature value at the segment";
CM_ SG_ 1217 Cv_Offset_Seg02 "Offset of the curvature value at the segment";
CM_ SG_ 1217 Cv_Offset_Seg03 "Offset of the curvature value at the segment";
CM_ SG_ 1217 Cv_Offset_Seg04 "Offset of the curvature value at the segment";
CM_ SG_ 1217 Cv_Offset_Seg05 "Offset of the curvature value at the segment";
CM_ SG_ 1217 Cv_Offset_Seg06 "Offset of the curvature value at the segment";
CM_ SG_ 1217 Cv_Offset_Seg07 "Offset of the curvature value at the segment";
CM_ SG_ 1217 Cv_Offset_Seg08 "Offset of the curvature value at the segment";
CM_ SG_ 1217 Cv_Offset_Seg09 "Offset of the curvature value at the segment";
CM_ SG_ 1217 Cv_Offset_Seg10 "Offset of the curvature value at the segment";
CM_ SG_ 1217 Cv_Offset_Seg11 "Offset of the curvature value at the segment";
CM_ SG_ 1217 Cv_Offset_Seg12 "Offset of the curvature value at the segment";
CM_ SG_ 1217 Cv_Offset_Seg13 "Offset of the curvature value at the segment";
CM_ SG_ 1217 Cv_Offset_Seg14 "Offset of the curvature value at the segment";
CM_ SG_ 1217 Cv_Offset_Seg15 "Offset of the curvature value at the segment";
CM_ SG_ 1217 Cv_Offset_Seg16 "Offset of the curvature value at the segment";
CM_ SG_ 1217 Cv_Offset_Seg17 "Offset of the curvature value at the segment";
CM_ SG_ 1217 Cv_Offset_Seg18 "Offset of the curvature value at the segment";
CM_ SG_ 1217 Cv_Offset_Seg19 "Offset of the curvature value at the segment";
CM_ BO_ 1220 "central line from 0 to  -20m";
CM_ SG_ 1218 centerline_1_CRC "CRC - Autosar E2E Profile 5";
CM_ SG_ 1218 centerline_1_AliveCtr "Alive counter - Autosar E2E Profile 5";
CM_ SG_ 1218 CenterPoint_dx_00 "Longitudinal distance to the center line point. Invalid if CenterPoint_dx_XX = 0.0 AND CenterPoint_dy_XX = -102.4";
CM_ SG_ 1218 CenterPoint_dy_00 "Lateral distance to the center line point. Invalid if CenterPoint_dx_XX = 0.0 AND CenterPoint_dy_XX = -102.4";
CM_ SG_ 1218 CenterPoint_dx_01 "Longitudinal distance to the center line point. Invalid if CenterPoint_dx_XX = 0.0 AND CenterPoint_dy_XX = -102.4";
CM_ SG_ 1218 CenterPoint_dy_01 "Lateral distance to the center line point. Invalid if CenterPoint_dx_XX = 0.0 AND CenterPoint_dy_XX = -102.4";
CM_ SG_ 1218 CenterPoint_dx_02 "Longitudinal distance to the center line point. Invalid if CenterPoint_dx_XX = 0.0 AND CenterPoint_dy_XX = -102.4";
CM_ SG_ 1218 CenterPoint_dy_02 "Lateral distance to the center line point. Invalid if CenterPoint_dx_XX = 0.0 AND CenterPoint_dy_XX = -102.4";
CM_ SG_ 1218 CenterPoint_dx_03 "Longitudinal distance to the center line point. Invalid if CenterPoint_dx_XX = 0.0 AND CenterPoint_dy_XX = -102.4";
CM_ SG_ 1218 CenterPoint_dy_03 "Lateral distance to the center line point. Invalid if CenterPoint_dx_XX = 0.0 AND CenterPoint_dy_XX = -102.4";
CM_ SG_ 1218 CenterPoint_dx_04 "Longitudinal distance to the center line point. Invalid if CenterPoint_dx_XX = 0.0 AND CenterPoint_dy_XX = -102.4";
CM_ SG_ 1218 CenterPoint_dy_04 "Lateral distance to the center line point. Invalid if CenterPoint_dx_XX = 0.0 AND CenterPoint_dy_XX = -102.4";
CM_ SG_ 1218 CenterPoint_dx_05 "Longitudinal distance to the center line point. Invalid if CenterPoint_dx_XX = 0.0 AND CenterPoint_dy_XX = -102.4";
CM_ SG_ 1218 CenterPoint_dy_05 "Lateral distance to the center line point. Invalid if CenterPoint_dx_XX = 0.0 AND CenterPoint_dy_XX = -102.4";
CM_ SG_ 1218 CenterPoint_dx_06 "Longitudinal distance to the center line point. Invalid if CenterPoint_dx_XX = 0.0 AND CenterPoint_dy_XX = -102.4";
CM_ SG_ 1218 CenterPoint_dy_06 "Lateral distance to the center line point. Invalid if CenterPoint_dx_XX = 0.0 AND CenterPoint_dy_XX = -102.4";
CM_ SG_ 1218 CenterPoint_dx_07 "Longitudinal distance to the center line point. Invalid if CenterPoint_dx_XX = 0.0 AND CenterPoint_dy_XX = -102.4";
CM_ SG_ 1218 CenterPoint_dy_07 "Lateral distance to the center line point. Invalid if CenterPoint_dx_XX = 0.0 AND CenterPoint_dy_XX = -102.4";
CM_ SG_ 1218 CenterPoint_dx_08 "Longitudinal distance to the center line point. Invalid if CenterPoint_dx_XX = 0.0 AND CenterPoint_dy_XX = -102.4";
CM_ SG_ 1218 CenterPoint_dy_08 "Lateral distance to the center line point. Invalid if CenterPoint_dx_XX = 0.0 AND CenterPoint_dy_XX = -102.4";
CM_ SG_ 1218 CenterPoint_dx_09 "Longitudinal distance to the center line point. Invalid if CenterPoint_dx_XX = 0.0 AND CenterPoint_dy_XX = -102.4";
CM_ SG_ 1218 CenterPoint_dy_09 "Lateral distance to the center line point. Invalid if CenterPoint_dx_XX = 0.0 AND CenterPoint_dy_XX = -102.4";
CM_ SG_ 1218 CenterPoint_dx_10 "Longitudinal distance to the center line point. Invalid if CenterPoint_dx_XX = 0.0 AND CenterPoint_dy_XX = -102.4";
CM_ SG_ 1218 CenterPoint_dy_10 "Lateral distance to the center line point. Invalid if CenterPoint_dx_XX = 0.0 AND CenterPoint_dy_XX = -102.4";
CM_ SG_ 1218 CenterPoint_dx_11 "Longitudinal distance to the center line point. Invalid if CenterPoint_dx_XX = 0.0 AND CenterPoint_dy_XX = -102.4";
CM_ SG_ 1218 CenterPoint_dy_11 "Lateral distance to the center line point. Invalid if CenterPoint_dx_XX = 0.0 AND CenterPoint_dy_XX = -102.4";
CM_ SG_ 1218 CenterPoint_dx_12 "Longitudinal distance to the center line point. Invalid if CenterPoint_dx_XX = 0.0 AND CenterPoint_dy_XX = -102.4";
CM_ SG_ 1218 CenterPoint_dy_12 "Lateral distance to the center line point. Invalid if CenterPoint_dx_XX = 0.0 AND CenterPoint_dy_XX = -102.4";
CM_ SG_ 1218 CenterPoint_dx_13 "Longitudinal distance to the center line point. Invalid if CenterPoint_dx_XX = 0.0 AND CenterPoint_dy_XX = -102.4";
CM_ SG_ 1218 CenterPoint_dy_13 "Lateral distance to the center line point. Invalid if CenterPoint_dx_XX = 0.0 AND CenterPoint_dy_XX = -102.4";
CM_ SG_ 1218 CenterPoint_dx_14 "Longitudinal distance to the center line point. Invalid if CenterPoint_dx_XX = 0.0 AND CenterPoint_dy_XX = -102.4";
CM_ SG_ 1218 CenterPoint_dy_14 "Lateral distance to the center line point. Invalid if CenterPoint_dx_XX = 0.0 AND CenterPoint_dy_XX = -102.4";
CM_ SG_ 1218 CenterPoint_dx_15 "Longitudinal distance to the center line point. Invalid if CenterPoint_dx_XX = 0.0 AND CenterPoint_dy_XX = -102.4";
CM_ SG_ 1218 CenterPoint_dy_15 "Lateral distance to the center line point. Invalid if CenterPoint_dx_XX = 0.0 AND CenterPoint_dy_XX = -102.4";
CM_ SG_ 1218 CenterPoint_dx_16 "Longitudinal distance to the center line point. Invalid if CenterPoint_dx_XX = 0.0 AND CenterPoint_dy_XX = -102.4";
CM_ SG_ 1218 CenterPoint_dy_16 "Lateral distance to the center line point. Invalid if CenterPoint_dx_XX = 0.0 AND CenterPoint_dy_XX = -102.4";
CM_ SG_ 1218 CenterPoint_dx_17 "Longitudinal distance to the center line point. Invalid if CenterPoint_dx_XX = 0.0 AND CenterPoint_dy_XX = -102.4";
CM_ SG_ 1218 CenterPoint_dy_17 "Lateral distance to the center line point. Invalid if CenterPoint_dx_XX = 0.0 AND CenterPoint_dy_XX = -102.4";
CM_ SG_ 1218 CenterPoint_dx_18 "Longitudinal distance to the center line point. Invalid if CenterPoint_dx_XX = 0.0 AND CenterPoint_dy_XX = -102.4";
CM_ SG_ 1218 CenterPoint_dy_18 "Lateral distance to the center line point. Invalid if CenterPoint_dx_XX = 0.0 AND CenterPoint_dy_XX = -102.4";
CM_ SG_ 1218 CenterPoint_dx_19 "Longitudinal distance to the center line point. Invalid if CenterPoint_dx_XX = 0.0 AND CenterPoint_dy_XX = -102.4";
CM_ SG_ 1218 CenterPoint_dy_19 "Lateral distance to the center line point. Invalid if CenterPoint_dx_XX = 0.0 AND CenterPoint_dy_XX = -102.4";
CM_ SG_ 1219 CenterPoint_dx_20 "Longitudinal distance to the center line point. Invalid if CenterPoint_dx_XX = 0.0 AND CenterPoint_dy_XX = -102.4";
CM_ SG_ 1219 CenterPoint_dy_20 "Lateral distance to the center line point. Invalid if CenterPoint_dx_XX = 0.0 AND CenterPoint_dy_XX = -102.4";
CM_ SG_ 1219 CenterPoint_dx_21 "Longitudinal distance to the center line point. Invalid if CenterPoint_dx_XX = 0.0 AND CenterPoint_dy_XX = -102.4";
CM_ SG_ 1219 CenterPoint_dy_21 "Lateral distance to the center line point. Invalid if CenterPoint_dx_XX = 0.0 AND CenterPoint_dy_XX = -102.4";
CM_ SG_ 1219 CenterPoint_dx_22 "Longitudinal distance to the center line point. Invalid if CenterPoint_dx_XX = 0.0 AND CenterPoint_dy_XX = -102.4";
CM_ SG_ 1219 CenterPoint_dy_22 "Lateral distance to the center line point. Invalid if CenterPoint_dx_XX = 0.0 AND CenterPoint_dy_XX = -102.4";
CM_ SG_ 1219 CenterPoint_dx_23 "Longitudinal distance to the center line point. Invalid if CenterPoint_dx_XX = 0.0 AND CenterPoint_dy_XX = -102.4";
CM_ SG_ 1219 CenterPoint_dy_23 "Lateral distance to the center line point. Invalid if CenterPoint_dx_XX = 0.0 AND CenterPoint_dy_XX = -102.4";
CM_ SG_ 1219 CenterPoint_dx_24 "Longitudinal distance to the center line point. Invalid if CenterPoint_dx_XX = 0.0 AND CenterPoint_dy_XX = -102.4";
CM_ SG_ 1219 CenterPoint_dy_24 "Lateral distance to the center line point. Invalid if CenterPoint_dx_XX = 0.0 AND CenterPoint_dy_XX = -102.4";
CM_ SG_ 1219 CenterPoint_dx_25 "Longitudinal distance to the center line point. Invalid if CenterPoint_dx_XX = 0.0 AND CenterPoint_dy_XX = -102.4";
CM_ SG_ 1219 CenterPoint_dy_25 "Lateral distance to the center line point. Invalid if CenterPoint_dx_XX = 0.0 AND CenterPoint_dy_XX = -102.4";
CM_ SG_ 1219 CenterPoint_dx_26 "Longitudinal distance to the center line point. Invalid if CenterPoint_dx_XX = 0.0 AND CenterPoint_dy_XX = -102.4";
CM_ SG_ 1219 CenterPoint_dy_26 "Lateral distance to the center line point. Invalid if CenterPoint_dx_XX = 0.0 AND CenterPoint_dy_XX = -102.4";
CM_ SG_ 1219 CenterPoint_dx_27 "Longitudinal distance to the center line point. Invalid if CenterPoint_dx_XX = 0.0 AND CenterPoint_dy_XX = -102.4";
CM_ SG_ 1219 CenterPoint_dy_27 "Lateral distance to the center line point. Invalid if CenterPoint_dx_XX = 0.0 AND CenterPoint_dy_XX = -102.4";
CM_ SG_ 1219 CenterPoint_dx_28 "Longitudinal distance to the center line point. Invalid if CenterPoint_dx_XX = 0.0 AND CenterPoint_dy_XX = -102.4";
CM_ SG_ 1219 CenterPoint_dy_28 "Lateral distance to the center line point. Invalid if CenterPoint_dx_XX = 0.0 AND CenterPoint_dy_XX = -102.4";
CM_ SG_ 1219 CenterPoint_dx_29 "Longitudinal distance to the center line point. Invalid if CenterPoint_dx_XX = 0.0 AND CenterPoint_dy_XX = -102.4";
CM_ SG_ 1219 CenterPoint_dy_29 "Lateral distance to the center line point. Invalid if CenterPoint_dx_XX = 0.0 AND CenterPoint_dy_XX = -102.4";
CM_ SG_ 1219 CenterPoint_dx_30 "Longitudinal distance to the center line point. Invalid if CenterPoint_dx_XX = 0.0 AND CenterPoint_dy_XX = -102.4";
CM_ SG_ 1219 CenterPoint_dy_30 "Lateral distance to the center line point. Invalid if CenterPoint_dx_XX = 0.0 AND CenterPoint_dy_XX = -102.4";
CM_ SG_ 1219 CenterPoint_dx_31 "Longitudinal distance to the center line point. Invalid if CenterPoint_dx_XX = 0.0 AND CenterPoint_dy_XX = -102.4";
CM_ SG_ 1219 CenterPoint_dy_31 "Lateral distance to the center line point. Invalid if CenterPoint_dx_XX = 0.0 AND CenterPoint_dy_XX = -102.4";
CM_ SG_ 1219 CenterPoint_dx_32 "Longitudinal distance to the center line point. Invalid if CenterPoint_dx_XX = 0.0 AND CenterPoint_dy_XX = -102.4";
CM_ SG_ 1219 CenterPoint_dy_32 "Lateral distance to the center line point. Invalid if CenterPoint_dx_XX = 0.0 AND CenterPoint_dy_XX = -102.4";
CM_ SG_ 1219 CenterPoint_dx_33 "Longitudinal distance to the center line point. Invalid if CenterPoint_dx_XX = 0.0 AND CenterPoint_dy_XX = -102.4";
CM_ SG_ 1219 CenterPoint_dy_33 "Lateral distance to the center line point. Invalid if CenterPoint_dx_XX = 0.0 AND CenterPoint_dy_XX = -102.4";
CM_ SG_ 1219 CenterPoint_dx_34 "Longitudinal distance to the center line point. Invalid if CenterPoint_dx_XX = 0.0 AND CenterPoint_dy_XX = -102.4";
CM_ SG_ 1219 CenterPoint_dy_34 "Lateral distance to the center line point. Invalid if CenterPoint_dx_XX = 0.0 AND CenterPoint_dy_XX = -102.4";
CM_ SG_ 1219 centerline_LaneWidth "current lane width";
CM_ SG_ 1219 localization_lat_StdDev "Localizer standard deviation lateral wrt ego vehicle coordinates";
CM_ SG_ 1219 localization_long_StdDev "Localizer standard deviation longitudinal wrt ego vehicle coordinates";
CM_ SG_ 1219 localization_heading_StdDev "Localizer standard deviation in heading";
CM_ SG_ 1219 map_position_deviation "Distance between map matched position and estimated position";
CM_ SG_ 1219 map_position_accuracy "Standard deviation of the offset";
CM_ SG_ 1219 Timestamp "Map data timestamp for synchronization";
CM_ BO_ 1221 "central line with high resolution up to 0.001m";
CM_ SG_ 1226 ReferenceLine1_CRC "CRC - Autosar E2E Profile 5";
CM_ SG_ 1226 ReferenceLine1_AliveCtr "Alive counter - Autosar E2E Profile 5";
CM_ SG_ 1226 ReferenceLine1_TimeStamp "Map data timestamp for synchronization";
CM_ SG_ 1226 ReferenceLine_point_N "Number of valid elements in the reference line";
CM_ SG_ 1226 ReferenceLine_dx_00 "Longitudinal distance to the reference line point";
CM_ SG_ 1226 ReferenceLine_dy_00 "Lateral distance to the reference line point";
CM_ SG_ 1227 ReferenceLine2_CRC "CRC - Autosar E2E Profile 5";
CM_ SG_ 1227 ReferenceLine2_AliveCtr "Alive counter - Autosar E2E Profile 5";
CM_ SG_ 1227 ReferenceLine2_TimeStamp "Map data timestamp for synchronization";
CM_ SG_ 1227 ReferenceLine_dx_20 "Longitudinal distance to the reference line point";
CM_ SG_ 1227 ReferenceLine_dy_20 "Lateral distance to the reference line point";
CM_ SG_ 1228 Ego_Lane_Info1_CRC "CRC - Autosar E2E Profile 5";
CM_ SG_ 1228 Ego_Lane_Info1_AliveCtr "Alive counter - Autosar E2E Profile 5";
CM_ SG_ 1228 Ego_Lane_Info1_TimeStamp "Map data timestamp for synchronization";
CM_ SG_ 1228 Ego_Lane_Map_Status "Validity of RSD map";
CM_ SG_ 1228 Ego_Lane_CurrentSpeedLimit "Current speed limit on the Ego Lane
159 indicates an unknown speed";
CM_ SG_ 1228 Ego_Lane_CurrentSpeedLimit_Type "type of the speed limit";
CM_ SG_ 1228 Ego_Lane_NextSpeedLimit_Value_1 "Next speed limit on ego lane";
CM_ SG_ 1228 Ego_Lane_NextSpeedLimit_Loc_1 "Next speed limit location on ego lane";
CM_ SG_ 1228 Ego_Lane_NextTopoLocation_1 "Next location of topology change";
CM_ SG_ 1228 Ego_Lane_NextTopoType_1 "Next type of topology change";
CM_ SG_ 1228 Ego_Lane_NextTopoSide_1 "Side of the next topology change";
CM_ SG_ 1228 Ego_Lane_NextTopoSide_2 "Side of the next topology change";
CM_ SG_ 1228 Ego_Lane_NextTopoSide_3 "Side of the next topology change";
CM_ SG_ 1228 Ego_Lane_NextTopoSide_4 "Side of the next topology change";
CM_ SG_ 1228 Ego_Lane_CurrBoundary_Type_R "Type of the boundary";
CM_ SG_ 1228 Ego_Lane_NextBoundary_Loc_R_1 "location of the next lane boundary change";
CM_ SG_ 1228 Ego_Lane_NextBoundary_Type_R_1 "Type of the boundary";
CM_ SG_ 1228 Ego_Lane_NextBoundary_Loc_R_2 "location of the next lane boundary change";
CM_ SG_ 1228 Ego_Lane_NextBoundary_Type_R_2 "Type of the boundary";
CM_ SG_ 1228 Ego_Lane_NextBoundary_Loc_R_3 "location of the next lane boundary change";
CM_ SG_ 1228 Ego_Lane_NextBoundary_Type_R_3 "Type of the boundary";
CM_ SG_ 1228 Ego_Lane_NextBoundary_Loc_R_4 "location of the next lane boundary change";
CM_ SG_ 1228 Ego_Lane_NextBoundary_Type_R_4 "Type of the boundary";
CM_ SG_ 1228 Ego_Lane_CurrBoundary_Type_L "Type of the boundary";
CM_ SG_ 1228 Ego_Lane_NextBoundary_Loc_L_1 "location of the next lane boundary change";
CM_ SG_ 1228 Ego_Lane_NextBoundary_Type_L_1 "Type of the boundary";
CM_ SG_ 1228 Ego_Lane_NextBoundary_Loc_L_2 "location of the next lane boundary change";
CM_ SG_ 1228 Ego_Lane_NextBoundary_Type_L_2 "Type of the boundary";
CM_ SG_ 1228 Ego_Lane_NextBoundary_Loc_L_3 "location of the next lane boundary change";
CM_ SG_ 1228 Ego_Lane_NextBoundary_Type_L_3 "Type of the boundary";
CM_ SG_ 1228 Ego_Lane_NextBoundary_Loc_L_4 "location of the next lane boundary change";
CM_ SG_ 1228 Ego_Lane_NextBoundary_Type_L_4 "Type of the boundary";
CM_ SG_ 1229 Ego_Lane_Info2_CRC "CRC - Autosar E2E Profile 5";
CM_ SG_ 1229 Ego_Lane_Info2_AliveCtr "Alive counter - Autosar E2E Profile 5";
CM_ SG_ 1229 Ego_Lane_Info2_TimeStamp "Map data timestamp for synchronization";
CM_ SG_ 1229 Ego_Lane_SpeedProfile_Near_N "Number of valid elements in speed profile";
CM_ SG_ 1229 Ego_Lane_SpeedProfile_Near_00 "Speed Profile from vehicle crowd";
CM_ SG_ 1229 Ego_Lane_SpeedProfile_Far_N "Number of valid elements in speed profile";
CM_ SG_ 1229 Ego_Lane_NextHotspot_Int_1 "intensity of the hotspot";
CM_ SG_ 1229 Ego_Lane_NextHotspot_Prob_1 "probability of the hotspot";
CM_ SG_ 1229 Ego_Lane_NextHotspot_Side_1 "Side of the lane change";
CM_ SG_ 1229 Ego_Lane_NextHotspot_Int_2 "intensity of the hotspot";
CM_ SG_ 1229 Ego_Lane_NextHotspot_Prob_2 "probability of the hotspot";
CM_ SG_ 1229 Ego_Lane_NextHotspot_Side_2 "Side of the lane change";
CM_ SG_ 1229 Ego_Lane_NextHotspot_Int_3 "intensity of the hotspot";
CM_ SG_ 1229 Ego_Lane_NextHotspot_Prob_3 "probability of the hotspot";
CM_ SG_ 1229 Ego_Lane_NextHotspot_Side_3 "Side of the lane change";
CM_ SG_ 1229 Ego_Lane_NextHotspot_Int_4 "intensity of the hotspot";
CM_ SG_ 1229 Ego_Lane_NextHotspot_Prob_4 "probability of the hotspot";
CM_ SG_ 1229 Ego_Lane_NextHotspot_Side_4 "Side of the lane change";
CM_ SG_ 1230 Left_Lane_Info_CRC "CRC - Autosar E2E Profile 5";
CM_ SG_ 1230 Left_Lane_Info_AliveCtr "Alive counter - Autosar E2E Profile 5";
CM_ SG_ 1230 Left_Lane_Info_TimeStamp "Map data timestamp for synchronization";
CM_ SG_ 1230 Left_Lane_Exists "Indicates if the lane exists";
CM_ SG_ 1230 Left_Lane_isOvertakeLane "Indicates if the lane is the overtake lane";
CM_ SG_ 1230 Left_Lane_Start_dx "Indicates when this lane starts";
CM_ SG_ 1230 Left_CurrentSpeedLimit "Current speed limit on the Ego Lane
159 indicates an unknown speed";
CM_ SG_ 1230 Left_CurrentSpeedLimit_Type "type of the speed limit";
CM_ SG_ 1230 Left_NextSpeedLimit_Value_1 "Next speed limit on left lane";
CM_ SG_ 1230 Left_NextSpeedLimit_Location_1 "Next speed limit location on left lane";
CM_ SG_ 1230 Left_NextSpeedLimit_Type_1 "type of the next speed limit";
CM_ SG_ 1230 Left_SpeedProfile_Far_N "Number of valid elements in speed profile";
CM_ SG_ 1230 Left_NextTopo_Loc_1 "Next location of topology change";
CM_ SG_ 1230 Left_NextTopo_Type_1 "Next type of topology change";
CM_ SG_ 1230 Left_NextTopo_Side_1 "Side of the next topology change";
CM_ SG_ 1230 Left_NextTopo_Side_2 "Side of the next topology change";
CM_ SG_ 1230 Left_NextTopo_Loc_3 "Next location of topology change";
CM_ SG_ 1230 Left_NextTopo_Type_3 "Next type of topology change";
CM_ SG_ 1230 Left_NextTopo_Side_3 "Side of the next topology change";
CM_ SG_ 1230 Left_NextTopo_Loc_4 "Next location of topology change";
CM_ SG_ 1230 Left_NextTopo_Type_4 "Next type of topology change";
CM_ SG_ 1230 Left_NextTopo_Side_4 "Side of the next topology change";
CM_ SG_ 1231 Right_Lane_Info_CRC "CRC - Autosar E2E Profile 5";
CM_ SG_ 1231 Right_Lane_Info_AliveCtr "Alive counter - Autosar E2E Profile 5";
CM_ SG_ 1231 Right_Lane_Info_TimeStamp "Map data timestamp for synchronization";
CM_ SG_ 1231 Right_Lane_Exists "Indicates if the lane exists";
CM_ SG_ 1231 Right_Lane_isOvertakeLane "Indicates if the lane is the overtake lane";
CM_ SG_ 1231 Right_Lane_Start_dx "Indicates when this lane starts";
CM_ SG_ 1231 Right_CurrentSpeedLimit "Current speed limit on the Ego Lane
159 indicates an unknown speed";
CM_ SG_ 1231 Right_CurrentSpeedLimit_Type "type of the speed limit";
CM_ SG_ 1231 Right_NextSpeedLimit_Value_1 "Next speed limit on left lane";
CM_ SG_ 1231 Right_NextSpeedLimit_Location_1 "Next speed limit location on left lane";
CM_ SG_ 1231 Right_NextSpeedLimit_Type_1 "type of the next speed limit";
CM_ SG_ 1231 Right_SpeedProfile_Far_N "Number of valid elements in speed profile";
CM_ SG_ 1231 Right_NextTopo_Loc_1 "Next location of topology change";
CM_ SG_ 1231 Right_NextTopo_Type_1 "Next type of topology change";
CM_ SG_ 1231 Right_NextTopo_Side_1 "Side of the next topology change";
CM_ SG_ 1231 Right_NextTopo_Side_2 "Side of the next topology change";
CM_ SG_ 1231 Right_NextTopo_Loc_3 "Next location of topology change";
CM_ SG_ 1231 Right_NextTopo_Type_3 "Next type of topology change";
CM_ SG_ 1231 Right_NextTopo_Side_3 "Side of the next topology change";
CM_ SG_ 1231 Right_NextTopo_Side_4 "Side of the next topology change";
CM_ SG_ 453 ADAS_1C5_CheckSum "ADAS_1C5_CheckSum";
CM_ SG_ 453 ADAS_1C5_AliveCounter "ADAS_1C5_AliveCounter";
CM_ SG_ 453 EPS_ActRoadWheelAngValue "Actual Road Wheel Angle";
CM_ SG_ 453 EPS_ActRPCTrq "Actual RPC torque request (TBT level)";
CM_ SG_ 453 EPS_LatDrvLvl12SrvAvl "Lateral level 12 driving service availability";
CM_ SG_ 453 EPS_IntRPCMaxTrq "Maximum internally allowed RPC torque for Level 2 (safety limit)(TBT level)";
CM_ SG_ 453 EPS_IntRPCMinTrq "Minimum internally allowed RPC torque for Level 2 (safety limit)(TBT level)";
CM_ SG_ 453 EPS_LatMCHptcWrnSrvAvl "Describes the availability of the Haptic Warning Service, availability to respond to a haptic request";
CM_ SG_ 453 EPS_ActRoadWheelAngState "State of signal ActRoadWheelAngleValue";
CM_ SG_ 453 EPS_LatMCRoadWheelAngActive "Lateral Motion Control feedback signal for the Road Wheel Angle service activation";
CM_ SG_ 1210 ACC_ICON_LADI "Displays the LADI-Icon in the bottom row as an indicator for lateral-danger";
CM_ SG_ 1210 ADAS_4BA_CheckSum "CheckSum";
CM_ SG_ 1210 EgoDistanceToRightLaneMarking "Provides the lateral distance of ego center to right lane marking";
CM_ SG_ 1210 CurvatureInformation "Provides the curve radius in m";
CM_ SG_ 1210 TrafficSignSpeedLimit "Displays the legal speed limit according to traffic signs";
CM_ SG_ 1210 SensorConeRearLeft "Displays the sensing area of the rear left radar";
CM_ SG_ 1210 SensorConeRearRight "Displays the sensing area of the rear right radar";
CM_ SG_ 1210 SensorConeFrontLeft "Displays the sensing area of the front left radar";
CM_ SG_ 1210 SensorConeFrontRight "Displays the sensing area of the front right radar";
CM_ SG_ 1210 SensorConeFrontCenter "Displays the sensing area of the front center radar";
CM_ SG_ 1210 NeighboringVehicle1VehicleType "Provides the type of the neihboring vehicle no. 1";
CM_ SG_ 1210 NeighboringVehicle1X "Provides the location of the neighboring vehicle no.1 as a longitudinal distance from ego center";
CM_ SG_ 1210 NeighboringVehicle1Y "Provides the location of the neighboring vehicle no.1 as a lateral distance from ego center";
CM_ SG_ 1210 NeighboringVehicle1AugmentedData "Provides additional information of the surrounding vehicle no. 1";
CM_ SG_ 1210 NeighboringVehicle2VehicleType "Provides the type of the neihboring vehicle no. 2";
CM_ SG_ 1210 NeighboringVehicle2X "Provides the location of the neighboring vehicle no.2 as a longitudinal distance from ego center";
CM_ SG_ 1210 NeighboringVehicle2Y "Provides the location of the neighboring vehicle no.2 as a lateral distance from ego center";
CM_ SG_ 1210 ADAS_4BA_AliveCounter "AliveCounter";
CM_ SG_ 1210 NeighboringVehicle2AugmentedData "Provides additional information of the surrounding vehicle no. 2";
CM_ SG_ 1210 NeighboringVehicle3VehicleType "Provides the type of the neihboring vehicle no. 3";
CM_ SG_ 1210 NeighboringVehicle3X "Provides the location of the neighboring vehicle no.3 as a longitudinal distance from ego center";
CM_ SG_ 1210 NeighboringVehicle3Y "Provides the location of the neighboring vehicle no.3 as a lateral distance from ego center";
CM_ SG_ 1210 NeighboringVehicle3AugmentedData "Provides additional information of the surrounding vehicle no. 3";
CM_ SG_ 1210 NeighboringVehicle4VehicleType "Provides the type of the neihboring vehicle no. 4";
CM_ SG_ 1210 NeighboringVehicle4X "Provides the location of the neighboring vehicle no.4 as a longitudinal distance from ego center";
CM_ SG_ 1210 NeighboringVehicle4Y "Provides the location of the neighboring vehicle no.4 as a lateral distance from ego center";
CM_ SG_ 1210 NeighboringVehicle4AugmentedData "Provides additional information of the surrounding vehicle no. 4";
CM_ SG_ 1210 NeighboringVehicle5VehicleType "Provides the type of the neihboring vehicle no. 5";
CM_ SG_ 1210 NeighboringVehicle5X "Provides the location of the neighboring vehicle no.5 as a longitudinal distance from ego center";
CM_ SG_ 1210 NeighboringVehicle5Y "Provides the location of the neighboring vehicle no.5 as a lateral distance from ego center";
CM_ SG_ 1210 NeighboringVehicle5AugmentedData "Provides additional information of the surrounding vehicle no. 5";
CM_ SG_ 1210 NeighboringVehicle6VehicleType "Provides the type of the neihboring vehicle no. 6";
CM_ SG_ 1210 NeighboringVehicle6X "Provides the location of the neighboring vehicle no.6 as a longitudinal distance from ego center";
CM_ SG_ 1210 LedHadState "Displays the HWA-hf system state visually by using two LED-panels on the cockpit";
CM_ SG_ 1210 NeighboringVehicle6Y "Provides the location of the neighboring vehicle no.6 as a lateral distance from ego center";
CM_ SG_ 1210 NeighboringVehicle6AugmentedData "Provides additional information of the surrounding vehicle no. 6";
CM_ SG_ 1210 NeighboringVehicle7VehicleType "Provides the type of the neihboring vehicle no. 7";
CM_ SG_ 1210 NeighboringVehicle7X "Provides the location of the neighboring vehicle no.7 as a longitudinal distance from ego center";
CM_ SG_ 1210 NeighboringVehicle7Y "Provides the location of the neighboring vehicle no.7 as a lateral distance from ego center";
CM_ SG_ 1210 NeighboringVehicle7AugmentedData "Provides additional information of the surrounding vehicle no. 7";
CM_ SG_ 1210 NeighboringVehicle8VehicleType "Provides the type of the neihboring vehicle no. 8";
CM_ SG_ 1210 HwaHfStatus "Indicates status / availability of the hands free control";
CM_ SG_ 1210 NeighboringVehicle8X "Provides the location of the neighboring vehicle no.8 as a longitudinal distance from ego center";
CM_ SG_ 1210 NeighboringVehicle8Y "Provides the location of the neighboring vehicle no.8 as a lateral distance from ego center";
CM_ SG_ 1210 NeighboringVehicle8AugmentedData "Provides additional information of the surrounding vehicle no. 8";
CM_ SG_ 1210 HwaHonStatus "Indicates status / availability of the hands on control";
CM_ SG_ 1210 HwaAccStatus "Indicates status / availability of the ACC control";
CM_ SG_ 1210 SetSpeed "Indicates the set speed for hands free control";
CM_ SG_ 1210 SetSpeedColor "Sets the color of the set speed digits";
CM_ SG_ 1210 DisplayedEgoSpeed "Indicates the actual speed";
CM_ SG_ 1210 DisplayedEgoSpeedColor "Sets the color of the set speed digits";
CM_ SG_ 1210 DisplayedLaneMarkingLeftType "Indicates the style of left lane marking";
CM_ SG_ 1210 DisplayedLaneMarkingLeftColor "Indicates the color of left lane marking";
CM_ SG_ 1210 DisplayedLaneMarkingRightType "Indicates the style of right lane marking";
CM_ SG_ 1210 DisplayedLaneMarkingRightColor "Indicates the color of right lane marking";
CM_ SG_ 1210 TimeGapSetValue "Indicates the set value for the time gap by using visual bars and/or a range symbol in front of the ego vehicle";
CM_ SG_ 1210 TimeGapColor "Sets the color of the displayed time gap";
CM_ SG_ 1210 EgoLaneChange "Indicates when the ego vehicle plans or performs a lane change";
CM_ SG_ 1210 DisplayedTextMessageId "Displays visual text notfications on the cockpit";
CM_ SG_ 1210 PopupTextMessage "Displays the text notification of ADAS_hmiDisplayedTextMessageId in pop-up style";
CM_ SG_ 1210 AudioNotificationId "Plays back an auditory sound notification, e.g. warning sound or speech message";
CM_ SG_ 1210 AuxiliarySymbol "Displays additional symbols or animations, e.g. coffee cup (fatigue detection), collision warning, hands-on animation, etc.)";
CM_ SG_ 1210 EgoLaneAssignment "determines in which lane ego is driving";
CM_ SG_ 1210 EgoDistanceToLeftLaneMarking "Provides the lateral distance of ego center to left lane marking";
CM_ BO_ 291 "Message emulated by HASy (originally sent by ACC as ACC_06, 0x122 on VW E-CAN)";
CM_ SG_ 291 ACC_pos_Sollbeschl_Grad_02_D "Empfehlung an den Triebstrangkoordinator , mit welchem betragsmäŸ©g maximalen positiven Gradienten eine ACC-Anforderung 'ACC_Sollbeschleunigung_02' einzuregeln ist.";
CM_ SG_ 291 ACC_neg_Sollbeschl_Grad_02_D "Empfehlung an den Triebstrangkoordinator , mit welchem betragsmäŸ©g maximalen negativen Gradienten eine ACC-Anforderung 'ACC_Sollbeschleunigung_02' einzuregeln ist.";
CM_ SG_ 291 ACC_Minimale_Bremsung_D "Im Falle eines gesetzten Bits wird vom ACC dem TSK angezeigt, dass es sich im Resume_Suspend_Mode befindet. In diesem Mode darf der TSK keine ECD-Bremsung anfordern, unabhä®§ig von der 'ACC_Sollbeschleunigungsanforderung'.";
CM_ SG_ 291 ACC_zul_Regelabw_unten_D "Anforderung an den Triebstrangkoordinator. Zulä³³iger Betrag der Abweichung zwischen angeforderter 'ACC_Sollbeschleunigung(_02)' und umzusetzender Sollbeschleunigung  im TSK. Im TSK wird, abhä®§ig vom Arbeitspunkt die Toleranz und die Sollbeschleunigung f";
CM_ SG_ 291 ACC_zul_Regelabw_oben_D "Anforderung an den Triebstrangkoordinator. Zulä³³iger Betrag der Abweichung zwischen angeforderter 'ACC_Sollbeschleunigung(_02)' und umzusetzender Sollbeschleunigung  im TSK. Im TSK wird, abhä®§ig vom Arbeitspunkt die Toleranz und die Sollbeschleunigung f";
CM_ SG_ 291 ACC_06_CheckSum_D "FÃ¼r MLB:
'Berechnung siehe Lastenheft 'Kommunikationsabsicherung fÃ¼r FlexRay und CAN''

Ab MQB und MLBevo:
'Berechnung siehe Lastenheft 'End-to-End Kommunikationsabsicherung''

Endwerte siehe Begleitdokument 'S-PDU Kennungsfolgen'";
CM_ SG_ 291 ACC_06_AliveCounter_D "ACC_06
_AliveCounter";
CM_ SG_ 602 ADAS_Req_Prefill "Prefill??";
CM_ SG_ 602 ADAS_Req_HBA "HBA??";
CM_ SG_ 602 ADAS_Req_AWB "AWB??";
CM_ SG_ 602 ADAS_Lvl_HBA "HBA??";
CM_ SG_ 602 ADAS_Lvl_AWB "AWB??";
CM_ SG_ 602 ADAS_DecelTyp_AEB "AEB?????";
CM_ SG_ 602 ADAS_Decel_AEB "AEB???";
CM_ SG_ 602 ADAS_25A_CheckSum "ADAS_259_?????(0x51)
ADAS_259_CheckSum
";
CM_ SG_ 602 ADAS_25A_AliveCounter "ADAS_259_?????
ADAS_259_AliveCounter";
CM_ SG_ 1554 HandoverIndication "Signal used to request driving handover to the vehicle";
BA_DEF_ SG_  "GenSigLongName" STRING ;
BA_DEF_  "BaudRate" FLOAT 0 4000000;
BA_DEF_  "ProtocolType" STRING ;
BA_DEF_  "BusNumber" INT 0 10;
BA_DEF_  "AutoRoute" INT 0 1;
BA_DEF_ BO_  "DiagState" ENUM  "No","Yes";
BA_DEF_ BO_  "DiagResponse" ENUM  "No","Yes";
BA_DEF_ BO_  "GenMsgSendType" ENUM  "cyclic","NoMsgSendType","IfActive","Event","CA","CE";
BA_DEF_ BO_  "GenMsgCycleTime" INT 0 0;
BA_DEF_ SG_  "GenSigSendType" ENUM  "cyclic","OnChange","OnWrite","IfActive","OnChangeWithRepetition","OnWriteWithRepetition","IfActiveWithRepetition","CA","CE","Event";
BA_DEF_ SG_  "GenSigStartValue" INT 0 0;
BA_DEF_ BO_  "GenMsgCycleTimeFast" INT 0 0;
BA_DEF_ BO_  "GenMsgNrOfRepetition" INT 0 0;
BA_DEF_ BO_  "GenMsgDelayTime" INT 0 0;
BA_DEF_  "DBName" STRING ;
BA_DEF_ BO_  "CANFD_BRS" ENUM  "0","1";
BA_DEF_ BO_  "VFrameFormat" ENUM  "StandardCAN","ExtendedCAN","reserved","reserved","reserved","reserved","reserved","reserved","reserved","reserved","reserved","reserved","reserved","reserved","StandardCAN_FD","ExtendedCAN_FD";
BA_DEF_  "BusBaudrateData" INT 0 10000;
BA_DEF_  "BusBaudrateOther" INT 0 10000;
BA_DEF_ BO_  "GenMsgILSupport" ENUM  "No","Yes";
BA_DEF_  "NmBaseAddress" HEX 1024 1087;
BA_DEF_  "BusType" STRING ;
BA_DEF_ SG_  "sigDespEng" STRING ;
BA_DEF_ SG_  "sigSecLevel" STRING ;
BA_DEF_ SG_  "sigConfig" STRING ;
BA_DEF_ SG_  "sigExplanation" STRING ;
BA_DEF_DEF_  "GenSigLongName" "";
BA_DEF_DEF_  "BaudRate" 2000000;
BA_DEF_DEF_  "ProtocolType" "CAN FD";
BA_DEF_DEF_  "BusNumber" 0;
BA_DEF_DEF_  "AutoRoute" 1;
BA_DEF_DEF_  "DiagState" "No";
BA_DEF_DEF_  "DiagResponse" "No";
BA_DEF_DEF_  "GenMsgSendType" "cyclic";
BA_DEF_DEF_  "GenMsgCycleTime" 0;
BA_DEF_DEF_  "GenSigSendType" "cyclic";
BA_DEF_DEF_  "GenSigStartValue" 0;
BA_DEF_DEF_  "GenMsgCycleTimeFast" 0;
BA_DEF_DEF_  "GenMsgNrOfRepetition" 0;
BA_DEF_DEF_  "GenMsgDelayTime" 0;
BA_DEF_DEF_  "DBName" "";
BA_DEF_DEF_  "CANFD_BRS" "1";
BA_DEF_DEF_  "VFrameFormat" "StandardCAN";
BA_DEF_DEF_  "BusBaudrateData" 2;
BA_DEF_DEF_  "BusBaudrateOther" 500;
BA_DEF_DEF_  "GenMsgILSupport" "Yes";
BA_DEF_DEF_  "NmBaseAddress" 1024;
BA_DEF_DEF_  "BusType" "CAN FD";
BA_DEF_DEF_  "sigDespEng" "";
BA_DEF_DEF_  "sigSecLevel" "QM";
BA_DEF_DEF_  "sigConfig" "";
BA_DEF_DEF_  "sigExplanation" "";
BA_ "BusNumber" 2;
BA_ "DBName" "BJEV_ADASCANFD";
BA_ "GenMsgCycleTime" BO_ 443 10;
BA_ "VFrameFormat" BO_ 443 14;
BA_ "GenMsgCycleTime" BO_ 601 20;
BA_ "VFrameFormat" BO_ 601 14;
BA_ "GenMsgCycleTime" BO_ 716 50;
BA_ "VFrameFormat" BO_ 716 14;
BA_ "GenMsgCycleTime" BO_ 449 10;
BA_ "VFrameFormat" BO_ 449 14;
BA_ "GenMsgCycleTime" BO_ 1216 100;
BA_ "VFrameFormat" BO_ 1216 14;
BA_ "GenMsgCycleTime" BO_ 1217 100;
BA_ "VFrameFormat" BO_ 1217 14;
BA_ "GenMsgCycleTime" BO_ 1220 100;
BA_ "VFrameFormat" BO_ 1220 14;
BA_ "GenMsgCycleTime" BO_ 1218 100;
BA_ "VFrameFormat" BO_ 1218 14;
BA_ "GenMsgCycleTime" BO_ 1219 100;
BA_ "VFrameFormat" BO_ 1219 14;
BA_ "GenMsgCycleTime" BO_ 1221 100;
BA_ "VFrameFormat" BO_ 1221 14;
BA_ "GenMsgCycleTime" BO_ 1226 100;
BA_ "VFrameFormat" BO_ 1226 14;
BA_ "GenMsgCycleTime" BO_ 1227 100;
BA_ "VFrameFormat" BO_ 1227 14;
BA_ "GenMsgCycleTime" BO_ 1228 100;
BA_ "VFrameFormat" BO_ 1228 14;
BA_ "GenMsgCycleTime" BO_ 1229 100;
BA_ "VFrameFormat" BO_ 1229 14;
BA_ "GenMsgCycleTime" BO_ 1230 100;
BA_ "VFrameFormat" BO_ 1230 14;
BA_ "GenMsgCycleTime" BO_ 1231 100;
BA_ "VFrameFormat" BO_ 1231 14;
BA_ "GenMsgCycleTime" BO_ 800 50;
BA_ "VFrameFormat" BO_ 800 14;
BA_ "GenMsgCycleTime" BO_ 453 10;
BA_ "VFrameFormat" BO_ 453 14;
BA_ "GenMsgCycleTime" BO_ 1210 50;
BA_ "VFrameFormat" BO_ 1210 14;
BA_ "GenMsgCycleTime" BO_ 291 20;
BA_ "VFrameFormat" BO_ 291 14;
BA_ "GenMsgCycleTime" BO_ 602 20;
BA_ "VFrameFormat" BO_ 602 14;
BA_ "GenMsgSendType" BO_ 1554 3;
BA_ "VFrameFormat" BO_ 1554 14;
BA_ "GenSigStartValue" SG_ 443 WhlTqMin 32768;
BA_ "GenSigLongName" SG_ 716 HODTchZone2Sts_h8HSC8 "Hod Touch Zone 2 Status";
BA_ "GenSigLongName" SG_ 716 HODTchZone1Sts_h8HSC8 "Hod Touch Zone 1 Status";
BA_ "GenSigLongName" SG_ 716 HODSysSts_h8HSC8 "Hands Off Detection System Status";
BA_ "GenSigLongName" SG_ 716 HODdiagSts_h8HSC8 "Hod Diagnose Status";
BA_ "GenSigLongName" SG_ 716 HODTchZone3Val_h8HSC8 "Hod Touch Zone 3 Value";
BA_ "GenSigLongName" SG_ 716 HODTchZone3Sts_h8HSC8 "Hod Touch Zone 3 Status";
BA_ "GenSigLongName" SG_ 716 HODTchZone2Val_h8HSC8 "Hod Touch Zone 2 Value";
BA_ "GenSigLongName" SG_ 716 HODTchZone1Val_h8HSC8 "Hod Touch Zone 1 Value";
BA_ "GenSigLongName" SG_ 716 HODDetnSts_h8HSC8 "Hands Off Detection Hands Detection";
BA_ "GenSigStartValue" SG_ 449 ADAS_RdWhlAgReq 9000;
BA_ "GenSigStartValue" SG_ 449 ADAS_ExtMaxRPCTrq 1024;
BA_ "GenSigStartValue" SG_ 449 ADAS_ExtMinRPCTrq 1024;
BA_ "GenSigStartValue" SG_ 1217 Cv_Offset_Seg00 1023;
BA_ "GenSigStartValue" SG_ 1217 Cv_Offset_Seg01 1023;
BA_ "GenSigStartValue" SG_ 1217 Cv_Offset_Seg02 1023;
BA_ "GenSigStartValue" SG_ 1217 Cv_Offset_Seg03 1023;
BA_ "GenSigStartValue" SG_ 1217 Cv_Offset_Seg04 1023;
BA_ "GenSigStartValue" SG_ 1217 Cv_Offset_Seg05 1023;
BA_ "GenSigStartValue" SG_ 1217 Cv_Offset_Seg06 1023;
BA_ "GenSigStartValue" SG_ 1217 Cv_Offset_Seg07 1023;
BA_ "GenSigStartValue" SG_ 1217 Cv_Offset_Seg08 1023;
BA_ "GenSigStartValue" SG_ 1217 Cv_Offset_Seg09 1023;
BA_ "GenSigStartValue" SG_ 1217 Cv_Offset_Seg10 1023;
BA_ "GenSigStartValue" SG_ 1217 Cv_Offset_Seg11 1023;
BA_ "GenSigStartValue" SG_ 1217 Cv_Offset_Seg12 1023;
BA_ "GenSigStartValue" SG_ 1217 Cv_Offset_Seg13 1023;
BA_ "GenSigStartValue" SG_ 1217 Cv_Offset_Seg14 1023;
BA_ "GenSigStartValue" SG_ 1217 Cv_Offset_Seg15 1023;
BA_ "GenSigStartValue" SG_ 1217 Cv_Offset_Seg16 1023;
BA_ "GenSigStartValue" SG_ 1217 Cv_Offset_Seg17 1023;
BA_ "GenSigStartValue" SG_ 1217 Cv_Offset_Seg18 1023;
BA_ "GenSigStartValue" SG_ 1217 Cv_Offset_Seg19 1023;
BA_ "GenSigStartValue" SG_ 1226 ReferenceLine_dy_00 2048;
BA_ "GenSigStartValue" SG_ 1226 ReferenceLine_dy_01 2048;
BA_ "GenSigStartValue" SG_ 1226 ReferenceLine_dy_02 2048;
BA_ "GenSigStartValue" SG_ 1226 ReferenceLine_dy_03 2048;
BA_ "GenSigStartValue" SG_ 1226 ReferenceLine_dy_04 2048;
BA_ "GenSigStartValue" SG_ 1226 ReferenceLine_dy_05 2048;
BA_ "GenSigStartValue" SG_ 1226 ReferenceLine_dy_06 2048;
BA_ "GenSigStartValue" SG_ 1226 ReferenceLine_dy_07 2048;
BA_ "GenSigStartValue" SG_ 1226 ReferenceLine_dy_08 2048;
BA_ "GenSigStartValue" SG_ 1226 ReferenceLine_dy_09 2048;
BA_ "GenSigStartValue" SG_ 1226 ReferenceLine_dy_10 2048;
BA_ "GenSigStartValue" SG_ 1226 ReferenceLine_dy_11 2048;
BA_ "GenSigStartValue" SG_ 1226 ReferenceLine_dy_12 2048;
BA_ "GenSigStartValue" SG_ 1226 ReferenceLine_dy_13 2048;
BA_ "GenSigStartValue" SG_ 1226 ReferenceLine_dy_14 2048;
BA_ "GenSigStartValue" SG_ 1226 ReferenceLine_dy_15 2048;
BA_ "GenSigStartValue" SG_ 1226 ReferenceLine_dy_16 2048;
BA_ "GenSigStartValue" SG_ 1226 ReferenceLine_dy_17 2048;
BA_ "GenSigStartValue" SG_ 1226 ReferenceLine_dy_18 2048;
BA_ "GenSigStartValue" SG_ 1227 ReferenceLine_dy_19 2048;
BA_ "GenSigStartValue" SG_ 1227 ReferenceLine_dy_20 2048;
BA_ "GenSigStartValue" SG_ 1227 ReferenceLine_dy_21 2048;
BA_ "GenSigStartValue" SG_ 1227 ReferenceLine_dy_22 2048;
BA_ "GenSigStartValue" SG_ 1227 ReferenceLine_dy_23 2048;
BA_ "GenSigStartValue" SG_ 1227 ReferenceLine_dy_24 2048;
BA_ "GenSigStartValue" SG_ 1227 ReferenceLine_dy_25 2048;
BA_ "GenSigStartValue" SG_ 1227 ReferenceLine_dy_26 2048;
BA_ "GenSigStartValue" SG_ 1227 ReferenceLine_dy_27 2048;
BA_ "GenSigStartValue" SG_ 1227 ReferenceLine_dy_28 2048;
BA_ "GenSigStartValue" SG_ 1227 ReferenceLine_dy_29 2048;
BA_ "GenSigStartValue" SG_ 1227 ReferenceLine_dy_30 2048;
BA_ "GenSigStartValue" SG_ 1227 ReferenceLine_dy_31 2048;
BA_ "GenSigStartValue" SG_ 1227 ReferenceLine_dy_32 2048;
BA_ "GenSigStartValue" SG_ 1227 ReferenceLine_dy_33 2048;
BA_ "GenSigStartValue" SG_ 1227 ReferenceLine_dy_34 2048;
BA_ "GenSigLongName" SG_ 800 DMSAdoWrnngDspCmdHSC4 "Driver Monitor System Audio Warning Display Command";
BA_ "GenSigLongName" SG_ 800 DMSAudReqHSC4 "Driver Monitor System Audible Request";
BA_ "GenSigLongName" SG_ 800 DMSDspCmdHSC4 "Driver Monitor System Display Command";
BA_ "GenSigLongName" SG_ 800 DMSHapticWrnngDspCmdHSC4 "Driver Monitor System Haptic Warning Display Command";
BA_ "GenSigLongName" SG_ 800 DMSStsHSC4 "Driver Monitor System Status";
BA_ "GenSigLongName" SG_ 800 DMSVbnLvlReqHSC4 "Driver Monitor System Vibration Level Request";
BA_ "GenSigLongName" SG_ 800 DMSWrnngReqHSC4 "Driver Monitor System Warning Request";
BA_ "GenSigLongName" SG_ 800 DMS_FrP01_ChecksumHSC4 "DMS_FrP01_Checksum";
BA_ "GenSigLongName" SG_ 800 DMS_FrP01_RolingCounterHSC4 "DMS_FrP01_RolingCounter";
BA_ "GenSigLongName" SG_ 800 DrvrAbnormBehvorHSC4 "Driver Abnormal Behaviour";
BA_ "GenSigLongName" SG_ 800 DrvrDstcnStsHSC4 "Driver Distraction Status";
BA_ "GenSigLongName" SG_ 800 DrvrFtgLvlHSC4 "Driver Fatigue Level";
BA_ "GenSigLongName" SG_ 800 DrvrGazeRgnHSC4 "Driver Gaze Region";
BA_ "GenSigLongName" SG_ 800 DrvrPrstHSC4 "Driver Present";
BA_ "GenSigLongName" SG_ 800 EyeOnRoadHSC4 "EyeOnRoad";
BA_ "GenSigLongName" SG_ 800 SpfngDetHSC4 "Spoofing Detected";
BA_ "GenSigStartValue" SG_ 453 EPS_ActRoadWheelAngValue 9000;
BA_ "GenSigStartValue" SG_ 453 EPS_ActRPCTrq 1024;
BA_ "GenSigStartValue" SG_ 453 EPS_IntRPCMaxTrq 1024;
BA_ "GenSigStartValue" SG_ 453 EPS_IntRPCMinTrq 1024;
BA_ "GenSigStartValue" SG_ 1210 NeighboringVehicle1X 42;
BA_ "GenSigStartValue" SG_ 1210 NeighboringVehicle2X 42;
BA_ "GenSigStartValue" SG_ 1210 NeighboringVehicle3X 42;
BA_ "GenSigStartValue" SG_ 1210 NeighboringVehicle4X 42;
BA_ "GenSigStartValue" SG_ 1210 NeighboringVehicle5X 42;
BA_ "GenSigStartValue" SG_ 1210 NeighboringVehicle6X 42;
BA_ "GenSigStartValue" SG_ 1210 NeighboringVehicle7X 42;
BA_ "GenSigStartValue" SG_ 1210 NeighboringVehicle8X 42;
BA_ "GenSigSendType" SG_ 1554 HandoverIndication 9;
VAL_ 443 ShiftInProgress 1 "shift in progress" 0 "no shift" ;
VAL_ 601 ADAS_Req_Prefill 1 "Active" 0 "Not Active" ;
VAL_ 601 ADAS_Req_HBA 1 "Active" 0 "Not active" ;
VAL_ 601 ADAS_Req_AWB 1 "Active" 0 "Not Active" ;
VAL_ 601 ADAS_Lvl_HBA 7 "Reserved" 6 "Reserved" 5 "Reserved" 4 "Reserved" 3 "Level 3" 2 "Level 2" 1 "Level 1" 0 "Level 0" ;
VAL_ 601 ADAS_Lvl_AWB 7 "Profile 7 -" 6 "Profile 6 -" 5 "Profile 5 - TOR lvl 2 HF" 4 "Profile 4 - TOR lvl 1 HF" 3 "Profile 3 - AEB strong brk. jerk" 2 "Profile 2 - AEB med. brk jerk" 1 "Profile 1 - AEB low brk jerk" 0 "No Request" ;
VAL_ 601 ADAS_DecelTyp_AEB 15 "Reserved" 14 "Reserved" 13 "Reserved" 12 "Reserved" 11 "Reserved" 10 "Reserved" 9 "Reserved" 8 "Reserved" 7 "Reserved" 6 "Reserved" 5 "FCTB" 4 "EBA" 3 "AEB~CYCLIST" 2 "AEB~VRU" 1 "AEB" 0 "Default" ;
VAL_ 716 HODTchZone2Sts_h8HSC8 7 "Reserved" 6 "Reserved" 5 "Reserved" 4 "Reserved" 3 "Reserved" 2 "Reserved" 1 "Hand detected" 0 "No hand detected" ;
VAL_ 716 HODTchZone1Sts_h8HSC8 7 "Reserved" 6 "Reserved" 5 "Reserved" 4 "Reserved" 3 "Reserved" 2 "Reserved" 1 "Hand detected" 0 "No hand detected" ;
VAL_ 716 HODSysSts_h8HSC8 7 "Reserved" 6 "Reserved" 5 "Reserved" 4 "No Calibration" 3 "Shutdown" 2 "Fault" 1 "Initial Status" 0 "Available" ;
VAL_ 716 HODdiagSts_h8HSC8 15 "Other state" 14 "Reserved" 13 "Reserved" 12 "Reserved" 11 "System Error" 10 "Coding Error" 9 "Overvoltage" 8 "Undervoltage" 7 "CPU Defect or Mat shortage" 6 "Sense Error" 5 "Guard Error" 4 "CPU Error" 3 "Watchdog Error" 2 "ROM Error" 1 "EEPROM" 0 "No Error" ;
VAL_ 716 HODTchZone3Sts_h8HSC8 7 "Reserved" 6 "Reserved" 5 "Reserved" 4 "Reserved" 3 "Reserved" 2 "Reserved" 1 "Hand detected" 0 "No hand detected" ;
VAL_ 716 HODDetnSts_h8HSC8 15 "Reserved" 14 "Reserved" 13 "Reserved" 12 "Reserved" 11 "Reserved" 10 "Reserved" 9 "Reserved" 8 "Reserved" 7 "Reserved" 6 "Reserved" 5 "Reserved" 4 "Reserved" 3 "Reserved" 2 "Valid contact detected" 1 "No valid contact detected" 0 "Unknown" ;
VAL_ 449 DADCSteerTqReqActive 2 "HF SteeringTorque request active" 1 "HO SteeringTorque request active" 0 "SteeringTorque req not active" ;
VAL_ 449 ADAS_RdWhlAgReqActive 2 "HF RdWhl AgReq active" 0 "RdWhlAgReq not active" 1 "HO RdWhlAgReq active" ;
VAL_ 1216 GF_NumberOfLanes 0 "wrong direction" 1 "1 lane" 2 "2 lanes" 3 "3 lanes" 4 "4 lanes" 5 "5 lanes" 6 "6 or more lanes" 7 "Unknown" ;
VAL_ 1216 GF_Region_outOfODD_offset 1023 "Not within horizon" ;
VAL_ 1216 GF_Country_outOfODD_offset 1023 "Not within horizon" ;
VAL_ 1216 GF_LaneTrans_outOfODD_offset 1023 "Not within horizon" ;
VAL_ 1216 GF_Curvature_outOfODD_offset 1023 "Not within horizon" ;
VAL_ 1216 GF_LaneType_outOfODD_offset 1023 "Not within horizon" ;
VAL_ 1216 GF_RoadSlope_outOfODD_offset 1023 "Not within horizon" ;
VAL_ 1216 GF_LaneWidth_outOfODD_offset 1023 "Not within horizon" ;
VAL_ 1216 GF_FormOfWay_outOfODD_offset 1023 "Not within horizon" ;
VAL_ 1216 GF_MapExpired 0 "0" 1 "1" ;
VAL_ 1216 GF_BlackListedSegment_offset 1023 "Not within horizon" ;
VAL_ 1216 GF_Intersection_offset 1023 "Not within horizon" ;
VAL_ 1216 GF_SideWind_offset 1023 "Not within horizon" ;
VAL_ 1216 GF_TollGate_offset 1023 "Not within ehorizon" ;
VAL_ 1216 GF_TrafficLight_offset 1023 "Not within ehorizon" ;
VAL_ 1216 GF_Tunnel_Offset 1023 "Not within ehorizon" ;
VAL_ 1216 GF_MapStatus 512 "MapTimeSyncStatus" 256 "GNSS signal error" 128 "RTK not available" 64 "Software Error" 32 "Hardware Error" 16 "Map data expired" 8 "Initialization" 4 "Local ECU not ready" 2 "Traffic line missing" 1 "Map not Ready" 0 "Map Ready" ;
VAL_ 1228 Ego_Lane_Map_Status 0 "INVALID" 1 "VALID" ;
VAL_ 1228 Ego_Lane_CurrentSpeedLimit_Type 0 "EFFECTIVE" 1 "IMPLICIT" 2 "UNKNOWN" 3 "RESERVED" ;
VAL_ 1228 Ego_Lane_NextSpeedLimit_Type_1 0 "EFFECTIVE" 1 "IMPLICIT" 2 "UNKNOWN" 3 "RESERVED" ;
VAL_ 1228 Ego_Lane_NextSpeedLimit_Type_2 0 "EFFECTIVE" 1 "IMPLICIT" 2 "UNKNOWN" 3 "RESERVED" ;
VAL_ 1228 Ego_Lane_NextSpeedLimit_Type_3 0 "EFFECTIVE" 1 "IMPLICIT" 2 "UNKNOWN" 3 "RESERVED" ;
VAL_ 1228 Ego_Lane_NextSpeedLimit_Type_4 0 "EFFECTIVE" 1 "IMPLICIT" 2 "UNKNOWN" 3 "RESERVED" ;
VAL_ 1228 Ego_Lane_NextTopoType_1 0 "UNKNOWN" 1 "OPENING" 2 "CLOSING" 3 "MERGING" 4 "SPLITTING" 5 "ROAD_MERGING" 6 "ROAD_SPLITTING" ;
VAL_ 1228 Ego_Lane_NextTopoSide_1 0 "LEFT" 1 "RIGHT" ;
VAL_ 1228 Ego_Lane_NextTopoType_2 0 "UNKNOWN" 1 "OPENING" 2 "CLOSING" 3 "MERGING" 4 "SPLITTING" 5 "ROAD_MERGING" 6 "ROAD_SPLITTING" ;
VAL_ 1228 Ego_Lane_NextTopoSide_2 0 "LEFT" 1 "RIGHT" ;
VAL_ 1228 Ego_Lane_NextTopoType_3 0 "UNKNOWN" 1 "OPENING" 2 "CLOSING" 3 "MERGING" 4 "SPLITTING" 5 "ROAD_MERGING" 6 "ROAD_SPLITTING" ;
VAL_ 1228 Ego_Lane_NextTopoSide_3 0 "LEFT" 1 "RIGHT" ;
VAL_ 1228 Ego_Lane_NextTopoType_4 0 "UNKNOWN" 1 "OPENING" 2 "CLOSING" 3 "MERGING" 4 "SPLITTING" 5 "ROAD_MERGING" 6 "ROAD_SPLITTING" ;
VAL_ 1228 Ego_Lane_NextTopoSide_4 0 "LEFT" 1 "RIGHT" ;
VAL_ 1228 Ego_Lane_CurrBoundary_Type_R 0 "TYPE_SOLID_LINE" 1 "TYPE_DASHED_LINE" 2 "TYPE_DOUBLE_DASHED_DASHED" 3 "TYPE_DOUBLE_DASHED_SOLID" 4 "TYPE_DOUBLE_SOLID_DASHED" 5 "TYPE_DOUBLE_SOLID_SOLID" 6 "TYPE_MULTIPLE" 7 "TYPE_MULTIPLE_WARNING" 8 "TYPE_CAR_POOL" 9 "TYPE_ASPHALT_JOIN" 10 "TYPE_BOTTS_DOTS" 11 "TYPE_ROAD_EDGE" 12 "TYPE_GUARDRAIL" 13 "TYPE_CURBSTONE" 14 "TYPE_WALL" 15 "TYPE_TRAFFIC_CONE" 16 "TYPE_DELINEATOR_POST" 17 "TYPE_PARKING_CAR" 18 "TYPE_UNKNOWN_RAISED" 19 "TYPE_UNKNOWN" ;
VAL_ 1228 Ego_Lane_NextBoundary_Type_R_1 0 "TYPE_SOLID_LINE" 1 "TYPE_DASHED_LINE" 2 "TYPE_DOUBLE_DASHED_DASHED" 3 "TYPE_DOUBLE_DASHED_SOLID" 4 "TYPE_DOUBLE_SOLID_DASHED" 5 "TYPE_DOUBLE_SOLID_SOLID" 6 "TYPE_MULTIPLE" 7 "TYPE_MULTIPLE_WARNING" 8 "TYPE_CAR_POOL" 9 "TYPE_ASPHALT_JOIN" 10 "TYPE_BOTTS_DOTS" 11 "TYPE_ROAD_EDGE" 12 "TYPE_GUARDRAIL" 13 "TYPE_CURBSTONE" 14 "TYPE_WALL" 15 "TYPE_TRAFFIC_CONE" 16 "TYPE_DELINEATOR_POST" 17 "TYPE_PARKING_CAR" 18 "TYPE_UNKNOWN_RAISED" 19 "TYPE_UNKNOWN" ;
VAL_ 1228 Ego_Lane_NextBoundary_Type_R_2 0 "TYPE_SOLID_LINE" 1 "TYPE_DASHED_LINE" 2 "TYPE_DOUBLE_DASHED_DASHED" 3 "TYPE_DOUBLE_DASHED_SOLID" 4 "TYPE_DOUBLE_SOLID_DASHED" 5 "TYPE_DOUBLE_SOLID_SOLID" 6 "TYPE_MULTIPLE" 7 "TYPE_MULTIPLE_WARNING" 8 "TYPE_CAR_POOL" 9 "TYPE_ASPHALT_JOIN" 10 "TYPE_BOTTS_DOTS" 11 "TYPE_ROAD_EDGE" 12 "TYPE_GUARDRAIL" 13 "TYPE_CURBSTONE" 14 "TYPE_WALL" 15 "TYPE_TRAFFIC_CONE" 16 "TYPE_DELINEATOR_POST" 17 "TYPE_PARKING_CAR" 18 "TYPE_UNKNOWN_RAISED" 19 "TYPE_UNKNOWN" ;
VAL_ 1228 Ego_Lane_NextBoundary_Type_R_3 0 "TYPE_SOLID_LINE" 1 "TYPE_DASHED_LINE" 2 "TYPE_DOUBLE_DASHED_DASHED" 3 "TYPE_DOUBLE_DASHED_SOLID" 4 "TYPE_DOUBLE_SOLID_DASHED" 5 "TYPE_DOUBLE_SOLID_SOLID" 6 "TYPE_MULTIPLE" 7 "TYPE_MULTIPLE_WARNING" 8 "TYPE_CAR_POOL" 9 "TYPE_ASPHALT_JOIN" 10 "TYPE_BOTTS_DOTS" 11 "TYPE_ROAD_EDGE" 12 "TYPE_GUARDRAIL" 13 "TYPE_CURBSTONE" 14 "TYPE_WALL" 15 "TYPE_TRAFFIC_CONE" 16 "TYPE_DELINEATOR_POST" 17 "TYPE_PARKING_CAR" 18 "TYPE_UNKNOWN_RAISED" 19 "TYPE_UNKNOWN" ;
VAL_ 1228 Ego_Lane_NextBoundary_Type_R_4 0 "TYPE_SOLID_LINE" 1 "TYPE_DASHED_LINE" 2 "TYPE_DOUBLE_DASHED_DASHED" 3 "TYPE_DOUBLE_DASHED_SOLID" 4 "TYPE_DOUBLE_SOLID_DASHED" 5 "TYPE_DOUBLE_SOLID_SOLID" 6 "TYPE_MULTIPLE" 7 "TYPE_MULTIPLE_WARNING" 8 "TYPE_CAR_POOL" 9 "TYPE_ASPHALT_JOIN" 10 "TYPE_BOTTS_DOTS" 11 "TYPE_ROAD_EDGE" 12 "TYPE_GUARDRAIL" 13 "TYPE_CURBSTONE" 14 "TYPE_WALL" 15 "TYPE_TRAFFIC_CONE" 16 "TYPE_DELINEATOR_POST" 17 "TYPE_PARKING_CAR" 18 "TYPE_UNKNOWN_RAISED" 19 "TYPE_UNKNOWN" ;
VAL_ 1228 Ego_Lane_CurrBoundary_Type_L 0 "TYPE_SOLID_LINE" 1 "TYPE_DASHED_LINE" 2 "TYPE_DOUBLE_DASHED_DASHED" 3 "TYPE_DOUBLE_DASHED_SOLID" 4 "TYPE_DOUBLE_SOLID_DASHED" 5 "TYPE_DOUBLE_SOLID_SOLID" 6 "TYPE_MULTIPLE" 7 "TYPE_MULTIPLE_WARNING" 8 "TYPE_CAR_POOL" 9 "TYPE_ASPHALT_JOIN" 10 "TYPE_BOTTS_DOTS" 11 "TYPE_ROAD_EDGE" 12 "TYPE_GUARDRAIL" 13 "TYPE_CURBSTONE" 14 "TYPE_WALL" 15 "TYPE_TRAFFIC_CONE" 16 "TYPE_DELINEATOR_POST" 17 "TYPE_PARKING_CAR" 18 "TYPE_UNKNOWN_RAISED" 19 "TYPE_UNKNOWN" ;
VAL_ 1228 Ego_Lane_NextBoundary_Type_L_1 0 "TYPE_SOLID_LINE" 1 "TYPE_DASHED_LINE" 2 "TYPE_DOUBLE_DASHED_DASHED" 3 "TYPE_DOUBLE_DASHED_SOLID" 4 "TYPE_DOUBLE_SOLID_DASHED" 5 "TYPE_DOUBLE_SOLID_SOLID" 6 "TYPE_MULTIPLE" 7 "TYPE_MULTIPLE_WARNING" 8 "TYPE_CAR_POOL" 9 "TYPE_ASPHALT_JOIN" 10 "TYPE_BOTTS_DOTS" 11 "TYPE_ROAD_EDGE" 12 "TYPE_GUARDRAIL" 13 "TYPE_CURBSTONE" 14 "TYPE_WALL" 15 "TYPE_TRAFFIC_CONE" 16 "TYPE_DELINEATOR_POST" 17 "TYPE_PARKING_CAR" 18 "TYPE_UNKNOWN_RAISED" 19 "TYPE_UNKNOWN" ;
VAL_ 1228 Ego_Lane_NextBoundary_Type_L_2 0 "TYPE_SOLID_LINE" 1 "TYPE_DASHED_LINE" 2 "TYPE_DOUBLE_DASHED_DASHED" 3 "TYPE_DOUBLE_DASHED_SOLID" 4 "TYPE_DOUBLE_SOLID_DASHED" 5 "TYPE_DOUBLE_SOLID_SOLID" 6 "TYPE_MULTIPLE" 7 "TYPE_MULTIPLE_WARNING" 8 "TYPE_CAR_POOL" 9 "TYPE_ASPHALT_JOIN" 10 "TYPE_BOTTS_DOTS" 11 "TYPE_ROAD_EDGE" 12 "TYPE_GUARDRAIL" 13 "TYPE_CURBSTONE" 14 "TYPE_WALL" 15 "TYPE_TRAFFIC_CONE" 16 "TYPE_DELINEATOR_POST" 17 "TYPE_PARKING_CAR" 18 "TYPE_UNKNOWN_RAISED" 19 "TYPE_UNKNOWN" ;
VAL_ 1228 Ego_Lane_NextBoundary_Type_L_3 0 "TYPE_SOLID_LINE" 1 "TYPE_DASHED_LINE" 2 "TYPE_DOUBLE_DASHED_DASHED" 3 "TYPE_DOUBLE_DASHED_SOLID" 4 "TYPE_DOUBLE_SOLID_DASHED" 5 "TYPE_DOUBLE_SOLID_SOLID" 6 "TYPE_MULTIPLE" 7 "TYPE_MULTIPLE_WARNING" 8 "TYPE_CAR_POOL" 9 "TYPE_ASPHALT_JOIN" 10 "TYPE_BOTTS_DOTS" 11 "TYPE_ROAD_EDGE" 12 "TYPE_GUARDRAIL" 13 "TYPE_CURBSTONE" 14 "TYPE_WALL" 15 "TYPE_TRAFFIC_CONE" 16 "TYPE_DELINEATOR_POST" 17 "TYPE_PARKING_CAR" 18 "TYPE_UNKNOWN_RAISED" 19 "TYPE_UNKNOWN" ;
VAL_ 1228 Ego_Lane_NextBoundary_Type_L_4 0 "TYPE_SOLID_LINE" 1 "TYPE_DASHED_LINE" 2 "TYPE_DOUBLE_DASHED_DASHED" 3 "TYPE_DOUBLE_DASHED_SOLID" 4 "TYPE_DOUBLE_SOLID_DASHED" 5 "TYPE_DOUBLE_SOLID_SOLID" 6 "TYPE_MULTIPLE" 7 "TYPE_MULTIPLE_WARNING" 8 "TYPE_CAR_POOL" 9 "TYPE_ASPHALT_JOIN" 10 "TYPE_BOTTS_DOTS" 11 "TYPE_ROAD_EDGE" 12 "TYPE_GUARDRAIL" 13 "TYPE_CURBSTONE" 14 "TYPE_WALL" 15 "TYPE_TRAFFIC_CONE" 16 "TYPE_DELINEATOR_POST" 17 "TYPE_PARKING_CAR" 18 "TYPE_UNKNOWN_RAISED" 19 "TYPE_UNKNOWN" ;
VAL_ 1229 Ego_Lane_NextHotspot_Type_1 0 "HOTSPOT_NONE" 1 "HOTSPOT_BRAKE" 2 "HOTSPOT_LC_IN" 3 "HOTSPOT_LC_OUT" 4 "HOTSPOT_STOP" 5 "RESERVED" 6 "RESERVED" 7 "RESERVED" ;
VAL_ 1229 Ego_Lane_NextHotspot_Side_1 0 "LEFT" 1 "RIGHT" ;
VAL_ 1229 Ego_Lane_NextHotspot_Type_2 0 "HOTSPOT_NONE" 1 "HOTSPOT_BRAKE" 2 "HOTSPOT_LC_IN" 3 "HOTSPOT_LC_OUT" 4 "HOTSPOT_STOP" 5 "RESERVED" 6 "RESERVED" 7 "RESERVED" ;
VAL_ 1229 Ego_Lane_NextHotspot_Side_2 0 "LEFT" 1 "RIGHT" ;
VAL_ 1229 Ego_Lane_NextHotspot_Type_3 0 "HOTSPOT_NONE" 1 "HOTSPOT_BRAKE" 2 "HOTSPOT_LC_IN" 3 "HOTSPOT_LC_OUT" 4 "HOTSPOT_STOP" 5 "RESERVED" 6 "RESERVED" 7 "RESERVED" ;
VAL_ 1229 Ego_Lane_NextHotspot_Side_3 0 "LEFT" 1 "RIGHT" ;
VAL_ 1229 Ego_Lane_NextHotspot_Type_4 0 "HOTSPOT_NONE" 1 "HOTSPOT_BRAKE" 2 "HOTSPOT_LC_IN" 3 "HOTSPOT_LC_OUT" 4 "HOTSPOT_STOP" 5 "RESERVED" 6 "RESERVED" 7 "RESERVED" ;
VAL_ 1229 Ego_Lane_NextHotspot_Side_4 0 "LEFT" 1 "RIGHT" ;
VAL_ 1230 Left_CurrentSpeedLimit_Type 0 "EFFECTIVE" 1 "IMPLICIT" 2 "UNKNOWN" 3 "RESERVED" ;
VAL_ 1230 Left_NextSpeedLimit_Type_1 0 "EFFECTIVE" 1 "IMPLICIT" 2 "UNKNOWN" 3 "RESERVED" ;
VAL_ 1230 Left_NextSpeedLimit_Type_2 0 "EFFECTIVE" 1 "IMPLICIT" 2 "UNKNOWN" 3 "RESERVED" ;
VAL_ 1230 Left_NextSpeedLimit_Type_3 0 "EFFECTIVE" 1 "IMPLICIT" 2 "UNKNOWN" 3 "RESERVED" ;
VAL_ 1230 Left_NextSpeedLimit_Type_4 0 "EFFECTIVE" 1 "IMPLICIT" 2 "UNKNOWN" 3 "RESERVED" ;
VAL_ 1230 Left_NextTopo_Type_1 0 "UNKNOWN" 1 "OPENING" 2 "CLOSING" 3 "MERGING" 4 "SPLITTING" 5 "ROAD_MERGING" 6 "ROAD_SPLITTING" ;
VAL_ 1230 Left_NextTopo_Side_1 0 "LEFT" 1 "RIGHT" ;
VAL_ 1230 Left_NextTopo_Type_2 0 "UNKNOWN" 1 "OPENING" 2 "CLOSING" 3 "MERGING" 4 "SPLITTING" 5 "ROAD_MERGING" 6 "ROAD_SPLITTING" ;
VAL_ 1230 Left_NextTopo_Side_2 0 "LEFT" 1 "RIGHT" ;
VAL_ 1230 Left_NextTopo_Type_3 0 "UNKNOWN" 1 "OPENING" 2 "CLOSING" 3 "MERGING" 4 "SPLITTING" 5 "ROAD_MERGING" 6 "ROAD_SPLITTING" ;
VAL_ 1230 Left_NextTopo_Side_3 0 "LEFT" 1 "RIGHT" ;
VAL_ 1230 Left_NextTopo_Type_4 0 "UNKNOWN" 1 "OPENING" 2 "CLOSING" 3 "MERGING" 4 "SPLITTING" 5 "ROAD_MERGING" 6 "ROAD_SPLITTING" ;
VAL_ 1230 Left_NextTopo_Side_4 0 "LEFT" 1 "RIGHT" ;
VAL_ 1231 Right_CurrentSpeedLimit_Type 0 "EFFECTIVE" 1 "IMPLICIT" 2 "UNKNOWN" 3 "RESERVED" ;
VAL_ 1231 Right_NextSpeedLimit_Type_1 0 "EFFECTIVE" 1 "IMPLICIT" 2 "UNKNOWN" 3 "RESERVED" ;
VAL_ 1231 Right_NextSpeedLimit_Type_2 0 "EFFECTIVE" 1 "IMPLICIT" 2 "UNKNOWN" 3 "RESERVED" ;
VAL_ 1231 Right_NextSpeedLimit_Type_3 0 "EFFECTIVE" 1 "IMPLICIT" 2 "UNKNOWN" 3 "RESERVED" ;
VAL_ 1231 Right_NextSpeedLimit_Type_4 0 "EFFECTIVE" 1 "IMPLICIT" 2 "UNKNOWN" 3 "RESERVED" ;
VAL_ 1231 Right_NextTopo_Type_1 0 "UNKNOWN" 1 "OPENING" 2 "CLOSING" 3 "MERGING" 4 "SPLITTING" 5 "ROAD_MERGING" 6 "ROAD_SPLITTING" ;
VAL_ 1231 Right_NextTopo_Side_1 0 "LEFT" 1 "RIGHT" ;
VAL_ 1231 Right_NextTopo_Type_2 0 "UNKNOWN" 1 "OPENING" 2 "CLOSING" 3 "MERGING" 4 "SPLITTING" 5 "ROAD_MERGING" 6 "ROAD_SPLITTING" ;
VAL_ 1231 Right_NextTopo_Side_2 0 "LEFT" 1 "RIGHT" ;
VAL_ 1231 Right_NextTopo_Type_3 0 "UNKNOWN" 1 "OPENING" 2 "CLOSING" 3 "MERGING" 4 "SPLITTING" 5 "ROAD_MERGING" 6 "ROAD_SPLITTING" ;
VAL_ 1231 Right_NextTopo_Side_3 0 "LEFT" 1 "RIGHT" ;
VAL_ 1231 Right_NextTopo_Type_4 0 "UNKNOWN" 1 "OPENING" 2 "CLOSING" 3 "MERGING" 4 "SPLITTING" 5 "ROAD_MERGING" 6 "ROAD_SPLITTING" ;
VAL_ 1231 Right_NextTopo_Side_4 0 "LEFT" 1 "RIGHT" ;
VAL_ 800 DMSAdoWrnngDspCmdHSC4 2 "On" 1 "Off" 0 "Unavailable" ;
VAL_ 800 DMSAudReqHSC4 2 "On" 1 "Off" 0 "Unavailable" ;
VAL_ 800 DMSDspCmdHSC4 2 "On" 1 "Off" 0 "Unavailable" ;
VAL_ 800 DMSHapticWrnngDspCmdHSC4 2 "On" 1 "Off" 0 "Unavailable" ;
VAL_ 800 DMSStsHSC4 5 "Initialization" 4 "Camera Blocked" 3 "Fault" 2 "Active" 1 "Standby" 0 "Off" ;
VAL_ 800 DMSVbnLvlReqHSC4 2 "On" 1 "Off" 0 "Unavailable" ;
VAL_ 800 DMSWrnngReqHSC4 2 "Distraction request" 1 "Fatigue request" 0 "No request" ;
VAL_ 800 DrvrAbnormBehvorHSC4 15 "Reserved" 14 "Reserved" 13 "Reserved" 12 "Reserved" 11 "Reserved" 10 "Reserved" 9 "Reserved" 8 "Reserved" 7 "Reserved" 6 "Reserved" 5 "Eating" 4 "Drinking water" 3 "Smoking" 2 "Telephone calls" 1 "No abnormal behaviour" 0 "Unknown" ;
VAL_ 800 DrvrDstcnStsHSC4 7 "Reserve" 6 "Reserve" 5 "Reserve" 4 "High level distraction" 3 "Middle level distraction" 2 "Low level distraction" 1 "No distraction" 0 "Unknown" ;
VAL_ 800 DrvrFtgLvlHSC4 7 "Reserve" 6 "Reserve" 5 "Reserve" 4 "High level Drowsiness" 3 "Middle level Drowsiness" 2 "Low level Drowsiness" 1 "No Drowsiness" 0 "Unknown" ;
VAL_ 800 DrvrGazeRgnHSC4 31 "reserved" 30 "reserved" 29 "reserved" 28 "reserved" 27 "reserved" 26 "reserved" 25 "reserved" 24 "reserved" 23 "reserved" 22 "reserved" 21 "reserved" 20 "reserved" 19 "reserved" 18 "reserved" 17 "reserved" 16 "Right Side door area" 15 "Left Side door area" 14 "Right Seat Foot Area &Workbench " 13 "Left Seat Foot Area" 12 "Steering Wheel(e.g.button area)" 11 "Middle Instrument Cluster£¨A/C,radio,etc.£©" 10 "Navigation Display" 9 "Head-up display" 8 "Central driver's Instrument Cluster(speed gauge,etc.)" 7 "Central Rear View Mirror" 6 "Right Side Window" 5 "Left Side Window" 4 "Right Rear View Mirror" 3 "Left Rear View Mirror" 2 "Copilot Side of Windscreen" 1 "Driver Side of Windscreen" 0 "Init/Unknown" ;
VAL_ 800 DrvrPrstHSC4 2 "Driver  Presence" 1 "Driver Not Presence" 0 "Unknown" ;
VAL_ 800 EyeOnRoadHSC4 3 "Eyes Off Road - non-driving task related region" 2 "Eyes Off Road - driving task related region" 1 "Eyes On Road" 0 "Unavailable" ;
VAL_ 800 SpfngDetHSC4 2 "Detected" 1 "Not Detected" 0 "Unknown" ;
VAL_ 453 EPS_LatDrvLvl12SrvAvl 0 "NotAvailable" 1 "FailureDetected" 2 "Available" 3 "Reserved" ;
VAL_ 453 EPS_LatMCHptcWrnSrvAvl 0 "NotAvailable" 1 "FailureDetected" 2 "Available" 3 "Reserved" ;
VAL_ 453 EPS_ActRoadWheelAngState 0 "NotAvailable" 1 "FailureDetected" 2 "Available" 3 "Reserved" ;
VAL_ 453 EPS_LatMCRoadWheelAngActive 0 "RdWhlAgReq not active" 1 "RdWhlAgReq active" ;
VAL_ 1210 ACC_ICON_LADI 2 "Blinking" 1 "Shown" 0 "Not shown" ;
VAL_ 1210 EgoDistanceToRightLaneMarking 1 "0x00...0x3F: distance positive" 2 "0x40...0x7F: distance negative" ;
VAL_ 1210 CurvatureInformation 1 "0x00...0x3F: distance positive" 2 "0x40...0x7F: distance negative" ;
VAL_ 1210 TrafficSignSpeedLimit 1 "0x00: no speed limit" 2 "0x01...0x1E: value of speed limit" ;
VAL_ 1210 SensorConeRearLeft 0 "0x00: no display" 1 "0x01: short cone gray" 2 "0x02: long cone gray" 3 "0x03: short cone red" ;
VAL_ 1210 SensorConeRearRight 0 "0x00: no display" 1 "0x01: short cone gray" 2 "0x02: long cone gray" 3 "0x03: short cone red" ;
VAL_ 1210 SensorConeFrontLeft 0 "0x00: no display" 1 "0x01: short cone gray" 2 "0x02: long cone gray" 3 "0x03: short cone red" ;
VAL_ 1210 SensorConeFrontRight 0 "0x00: no display" 1 "0x01: short cone gray" 2 "0x02: long cone gray" 3 "0x03: short cone red" ;
VAL_ 1210 SensorConeFrontCenter 0 "0x00: no display" 1 "0x01: short cone gray" 2 "0x02: long cone gray" 3 "0x03: short cone red" ;
VAL_ 1210 NeighboringVehicle1VehicleType 0 "0x00: vehicle not present" 1 "0x01: passenger car" 2 "0x02: truck" 3 "0x03: motorbike" 4 "0x04: other" 5 "0x05: reserved" 6 "0x06: reserved" 7 "0x07: error" ;
VAL_ 1210 NeighboringVehicle1X 1 "0x00...0xFF: distance (positive values are left, negative values right from ego center)" ;
VAL_ 1210 NeighboringVehicle1Y 1 "0x00...0x7F: distance left from ego center" 2 "0x80...0xFF: distance right from ego center" ;
VAL_ 1210 NeighboringVehicle1AugmentedData 0 "0x00: normalDriving" 1 "0x01: selected as lead vehicle" 2 "0x02: located in ego blind spot" 3 "0x03: close distance to ego" 4 "0x04: strong deceleration" 5 "0x05: strong acceleration" 6 "0x06: lane change to left" 7 "0x07: lane change to right" ;
VAL_ 1210 NeighboringVehicle2VehicleType 0 "0x00: vehicle not present" 1 "0x01: passenger car" 2 "0x02: truck" 3 "0x03: motorbike" 4 "0x04: other" 5 "0x05: reserved" 6 "0x06: reserved" 7 "0x07: error" ;
VAL_ 1210 NeighboringVehicle2X 1 "0x00...0xFF: distance (positive values are left, negative values right from ego center)" ;
VAL_ 1210 NeighboringVehicle2Y 1 "0x00...0x7F: distance left from ego center" 2 "0x80...0xFF: distance right from ego center" ;
VAL_ 1210 NeighboringVehicle2AugmentedData 0 "0x00: normalDriving" 1 "0x01: selected as lead vehicle" 2 "0x02: located in ego blind spot" 3 "0x03: close distance to ego" 4 "0x04: strong deceleration" 5 "0x05: strong acceleration" 6 "0x06: lane change to left" 7 "0x07: lane change to right" ;
VAL_ 1210 NeighboringVehicle3VehicleType 0 "0x00: vehicle not present" 1 "0x01: passenger car" 2 "0x02: truck" 3 "0x03: motorbike" 4 "0x04: other" 5 "0x05: reserved" 6 "0x06: reserved" 7 "0x07: error" ;
VAL_ 1210 NeighboringVehicle3X 1 "0x00...0xFF: distance (positive values are left, negative values right from ego center)" ;
VAL_ 1210 NeighboringVehicle3Y 1 "0x00...0x7F: distance left from ego center" 2 "0x80...0xFF: distance right from ego center" ;
VAL_ 1210 NeighboringVehicle3AugmentedData 0 "0x00: normalDriving" 1 "0x01: selected as lead vehicle" 2 "0x02: located in ego blind spot" 3 "0x03: close distance to ego" 4 "0x04: strong deceleration" 5 "0x05: strong acceleration" 6 "0x06: lane change to left" 7 "0x07: lane change to right" ;
VAL_ 1210 NeighboringVehicle4VehicleType 0 "0x00: vehicle not present" 1 "0x01: passenger car" 2 "0x02: truck" 3 "0x03: motorbike" 4 "0x04: other" 5 "0x05: reserved" 6 "0x06: reserved" 7 "0x07: error" ;
VAL_ 1210 NeighboringVehicle4X 1 "0x00...0xFF: distance (positive values are left, negative values right from ego center)" ;
VAL_ 1210 NeighboringVehicle4Y 1 "0x00...0x7F: distance left from ego center" 2 "0x80...0xFF: distance right from ego center" ;
VAL_ 1210 NeighboringVehicle4AugmentedData 0 "0x00: normalDriving" 1 "0x01: selected as lead vehicle" 2 "0x02: located in ego blind spot" 3 "0x03: close distance to ego" 4 "0x04: strong deceleration" 5 "0x05: strong acceleration" 6 "0x06: lane change to left" 7 "0x07: lane change to right" ;
VAL_ 1210 NeighboringVehicle5VehicleType 0 "0x00: vehicle not present" 1 "0x01: passenger car" 2 "0x02: truck" 3 "0x03: motorbike" 4 "0x04: other" 5 "0x05: reserved" 6 "0x06: reserved" 7 "0x07: error" ;
VAL_ 1210 NeighboringVehicle5X 1 "0x00...0xFF: distance (positive values are left, negative values right from ego center)" ;
VAL_ 1210 NeighboringVehicle5Y 1 "0x00...0x7F: distance left from ego center" 2 "0x80...0xFF: distance right from ego center" ;
VAL_ 1210 NeighboringVehicle5AugmentedData 0 "0x00: normalDriving" 1 "0x01: selected as lead vehicle" 2 "0x02: located in ego blind spot" 3 "0x03: close distance to ego" 4 "0x04: strong deceleration" 5 "0x05: strong acceleration" 6 "0x06: lane change to left" 7 "0x07: lane change to right" ;
VAL_ 1210 NeighboringVehicle6VehicleType 0 "0x00: vehicle not present" 1 "0x01: passenger car" 2 "0x02: truck" 3 "0x03: motorbike" 4 "0x04: other" 5 "0x05: reserved" 6 "0x06: reserved" 7 "0x07: error" ;
VAL_ 1210 NeighboringVehicle6X 1 "0x00...0xFF: distance (positive values are left, negative values right from ego center)" ;
VAL_ 1210 LedHadState 15 "reserved5" 14 "reserved4" 13 "reserved3" 12 "reserved2" 11 "reserved1" 10 "minimalRiskManeuverState" 9 "takeOverRequestEmergencyState" 8 "takeOverRequestState" 7 "handsOnState" 6 "activePreWarningState" 5 "activeControlState" 4 "requestState" 3 "readyState" 2 "passiveState" 1 "initState" 0 "offState" ;
VAL_ 1210 NeighboringVehicle6Y 1 "0x00...0x7F: distance left from ego center" 2 "0x80...0xFF: distance right from ego center" ;
VAL_ 1210 NeighboringVehicle6AugmentedData 0 "0x00: normalDriving" 1 "0x01: selected as lead vehicle" 2 "0x02: located in ego blind spot" 3 "0x03: close distance to ego" 4 "0x04: strong deceleration" 5 "0x05: strong acceleration" 6 "0x06: lane change to left" 7 "0x07: lane change to right" ;
VAL_ 1210 NeighboringVehicle7VehicleType 0 "0x00: vehicle not present" 1 "0x01: passenger car" 2 "0x02: truck" 3 "0x03: motorbike" 4 "0x04: other" 5 "0x05: reserved" 6 "0x06: reserved" 7 "0x07: error" ;
VAL_ 1210 NeighboringVehicle7X 1 "0x00...0xFF: distance (positive values are left, negative values right from ego center)" ;
VAL_ 1210 NeighboringVehicle7Y 1 "0x00...0x7F: distance left from ego center" 2 "0x80...0xFF: distance right from ego center" ;
VAL_ 1210 NeighboringVehicle7AugmentedData 0 "0x00: normalDriving" 1 "0x01: selected as lead vehicle" 2 "0x02: located in ego blind spot" 3 "0x03: close distance to ego" 4 "0x04: strong deceleration" 5 "0x05: strong acceleration" 6 "0x06: lane change to left" 7 "0x07: lane change to right" ;
VAL_ 1210 NeighboringVehicle8VehicleType 0 "0x00: vehicle not present" 1 "0x01: passenger car" 2 "0x02: truck" 3 "0x03: motorbike" 4 "0x04: other" 5 "0x05: reserved" 6 "0x06: reserved" 7 "0x07: error" ;
VAL_ 1210 HwaHfStatus 0 "0x00: no display" 1 "0x01: not availabe" 2 "0x02: available" 3 "0x03: active" 4 "0x04: longitudinal override" 5 "0x05: lateral override" 6 "0x06: error" 7 "0x07: reserved" ;
VAL_ 1210 NeighboringVehicle8X 1 "0x00...0xFF: distance (positive values are left, negative values right from ego center)" ;
VAL_ 1210 NeighboringVehicle8Y 1 "0x00...0x7F: distance left from ego center" 2 "0x80...0xFF: distance right from ego center" ;
VAL_ 1210 NeighboringVehicle8AugmentedData 0 "0x00: normalDriving" 1 "0x01: selected as lead vehicle" 2 "0x02: located in ego blind spot" 3 "0x03: close distance to ego" 4 "0x04: strong deceleration" 5 "0x05: strong acceleration" 6 "0x06: lane change to left" 7 "0x07: lane change to right" ;
VAL_ 1210 HwaHonStatus 0 "0x00: no display" 1 "0x01: not availabe" 2 "0x02: available" 3 "0x03: active" 4 "0x04: longitudinal override" 5 "0x05: lateral override" 6 "0x06: error" 7 "0x07: reserved" ;
VAL_ 1210 HwaAccStatus 0 "0x00: no display" 1 "0x01: not availabe" 2 "0x02: available" 3 "0x03: active" 4 "0x04: longitudinal override" 5 "0x05: lateral override" 6 "0x06: error" 7 "0x07: reserved" ;
VAL_ 1210 SetSpeed 1 "0...254: set speed" 2 "255: reserved" ;
VAL_ 1210 SetSpeedColor 0 "0x00: no display" 1 "0x01: gray" 2 "0x02: white" 3 "0x03: green" 4 "0x04: yellow" 5 "0x05: red" 6 "0x06: blue" 7 "0x07: reserved" ;
VAL_ 1210 DisplayedEgoSpeed 1 "0...254: set speed" 2 "255: reserved" ;
VAL_ 1210 DisplayedEgoSpeedColor 0 "0x00: no display" 1 "0x01: gray" 2 "0x02: white" 3 "0x03: green" 4 "0x04: yellow" 5 "0x05: red" 6 "0x06: blue" 7 "0x07: reserved" ;
VAL_ 1210 DisplayedLaneMarkingLeftType 0 "0x00: dashed line" 1 "0x01: solid line" 2 "0x02: neighboring lane blocked" 3 "0x03: reserved" ;
VAL_ 1210 DisplayedLaneMarkingLeftColor 0 "0x00: no display" 1 "0x01: gray" 2 "0x02: white" 3 "0x03: green" 4 "0x04: yellow" 5 "0x05: red" 6 "0x06: blue" 7 "0x07: red flashing" ;
VAL_ 1210 DisplayedLaneMarkingRightType 0 "0x00: dashed line" 1 "0x01: solid line" 2 "0x02: neighboring lane blocked" 3 "0x03: reserved" ;
VAL_ 1210 DisplayedLaneMarkingRightColor 0 "0x00: no display" 1 "0x01: gray" 2 "0x02: white" 3 "0x03: green" 4 "0x04: yellow" 5 "0x05: red" 6 "0x06: blue" 7 "0x07: red flashing" ;
VAL_ 1210 TimeGapSetValue 0 "0x00: time gap 0 (closest)" 1 "0x01: time gap 1" 2 "0x02: time gap 2" 3 "0x03: time gap 3" 4 "0x04: time gap 4" 5 "0x05: time gap 5 (farest)" 6 "0x06: reserved" 7 "0x07: reserved" ;
VAL_ 1210 TimeGapColor 0 "0x00: no display" 1 "0x01: gray" 2 "0x02: white" 3 "0x03: green" 4 "0x04: yellow" 5 "0x05: red" 6 "0x06: blue" 7 "0x07: red flashing" ;
VAL_ 1210 EgoLaneChange 0 "0x00: normal driving" 1 "0x01: lane change intention to the left" 2 "0x02: lane change to the left in progress" 3 "0x03: lane change to the left completed" 4 "0x04: lane change intention to the right" 5 "0x05: lane change to the right in progress" 6 "0x06: lane change to the right completed" 7 "0x07: reserved" ;
VAL_ 1210 DisplayedTextMessageId 0 "0x00: no display" 1 "0x01: HWA handsfree not available" 2 "0x02: Unreleased highway section" 3 "0x03: Road condition insufficient" 4 "0x04: Lane markings not present" 5 "0x05: ESP intervention" 6 "0x06: ESP not available" 7 "0x07: Camera unable to see face" 8 "0x08: Seatbelt unfastened" 9 "0x09: Outside speed range" 10 "0x0A: Neighbouring vehicle too close" 11 "0x0B: Front vehicle too close" 12 "0x0C: Driver not focused on the road" 13 "0x0D: Please take a break / Drowsiness detected" 14 "0x0E: Wrong gear selected" 15 "0x0F: Behave according to the intended system usage" 16 "0x10: Please focus on the road" 17 "0x11: Approaching unreleased highway section in 1000 m" 18 "0x...: tbd" ;
VAL_ 1210 PopupTextMessage 0 "0x00: normal text notification (e.g. top middle of the cockpit screen)" 1 "0x01: displayed as prominent pop-up message in a box in the center of the cockpit" 2 "0x02: pop-up on the right side" 3 "0x03: pop-up on the left side" ;
VAL_ 1210 AudioNotificationId 0 "0x00: no sound notification" 1 "0x01: notification" 2 "0x02: warning" 3 "0x03: minimal risk maneuver (safe-stop)" ;
VAL_ 1210 AuxiliarySymbol 0 "0x00: no display" 1 "0x01: coffee cup" 2 "0x02: collision warning" 3 "0x03: hands-on animation (take over request)" ;
VAL_ 1210 EgoLaneAssignment 0 "0x00: emergeny lane" 1 "0x01: 1st next to emergency lane" 2 "0x02: 2nd next to emergency lane" 3 "0x03: 3rd next to emergency lane" ;
VAL_ 1210 EgoDistanceToLeftLaneMarking 1 "0x00...0x3F: distance positive" 2 "0x40...0x7F: distance negative" ;
VAL_ 291 ACC_Minimale_Bremsung_D 1 "Anford_Min_Bremsung_aktiv" 0 "Anford_Min_Bremsung_nicht_aktiv" ;
VAL_ 602 ADAS_Req_Prefill 1 "Active" 0 "Not Active" ;
VAL_ 602 ADAS_Req_HBA 1 "Active" 0 "Not active" ;
VAL_ 602 ADAS_Req_AWB 1 "Active" 0 "Not Active" ;
VAL_ 602 ADAS_Lvl_HBA 7 "Reserved" 6 "Reserved" 5 "Reserved" 4 "Reserved" 3 "Level 3" 2 "Level 2" 1 "Level 1" 0 "Level 0" ;
VAL_ 602 ADAS_Lvl_AWB 7 "Profile 7 -" 6 "Profile 6 -" 5 "Profile 5 - TOR lvl 2 HF" 4 "Profile 4 - TOR lvl 1 HF" 3 "Profile 3 - AEB strong brk. jerk" 2 "Profile 2 - AEB med. brk jerk" 1 "Profile 1 - AEB low brk jerk" 0 "No Request" ;
VAL_ 602 ADAS_DecelTyp_AEB 15 "Reserved" 14 "Reserved" 13 "Reserved" 12 "Reserved" 11 "Reserved" 10 "Reserved" 9 "Reserved" 8 "Reserved" 7 "Reserved" 6 "Reserved" 5 "FCTB" 4 "EBA" 3 "AEB~CYCLIST" 2 "AEB~VRU" 1 "AEB" 0 "Default" ;
